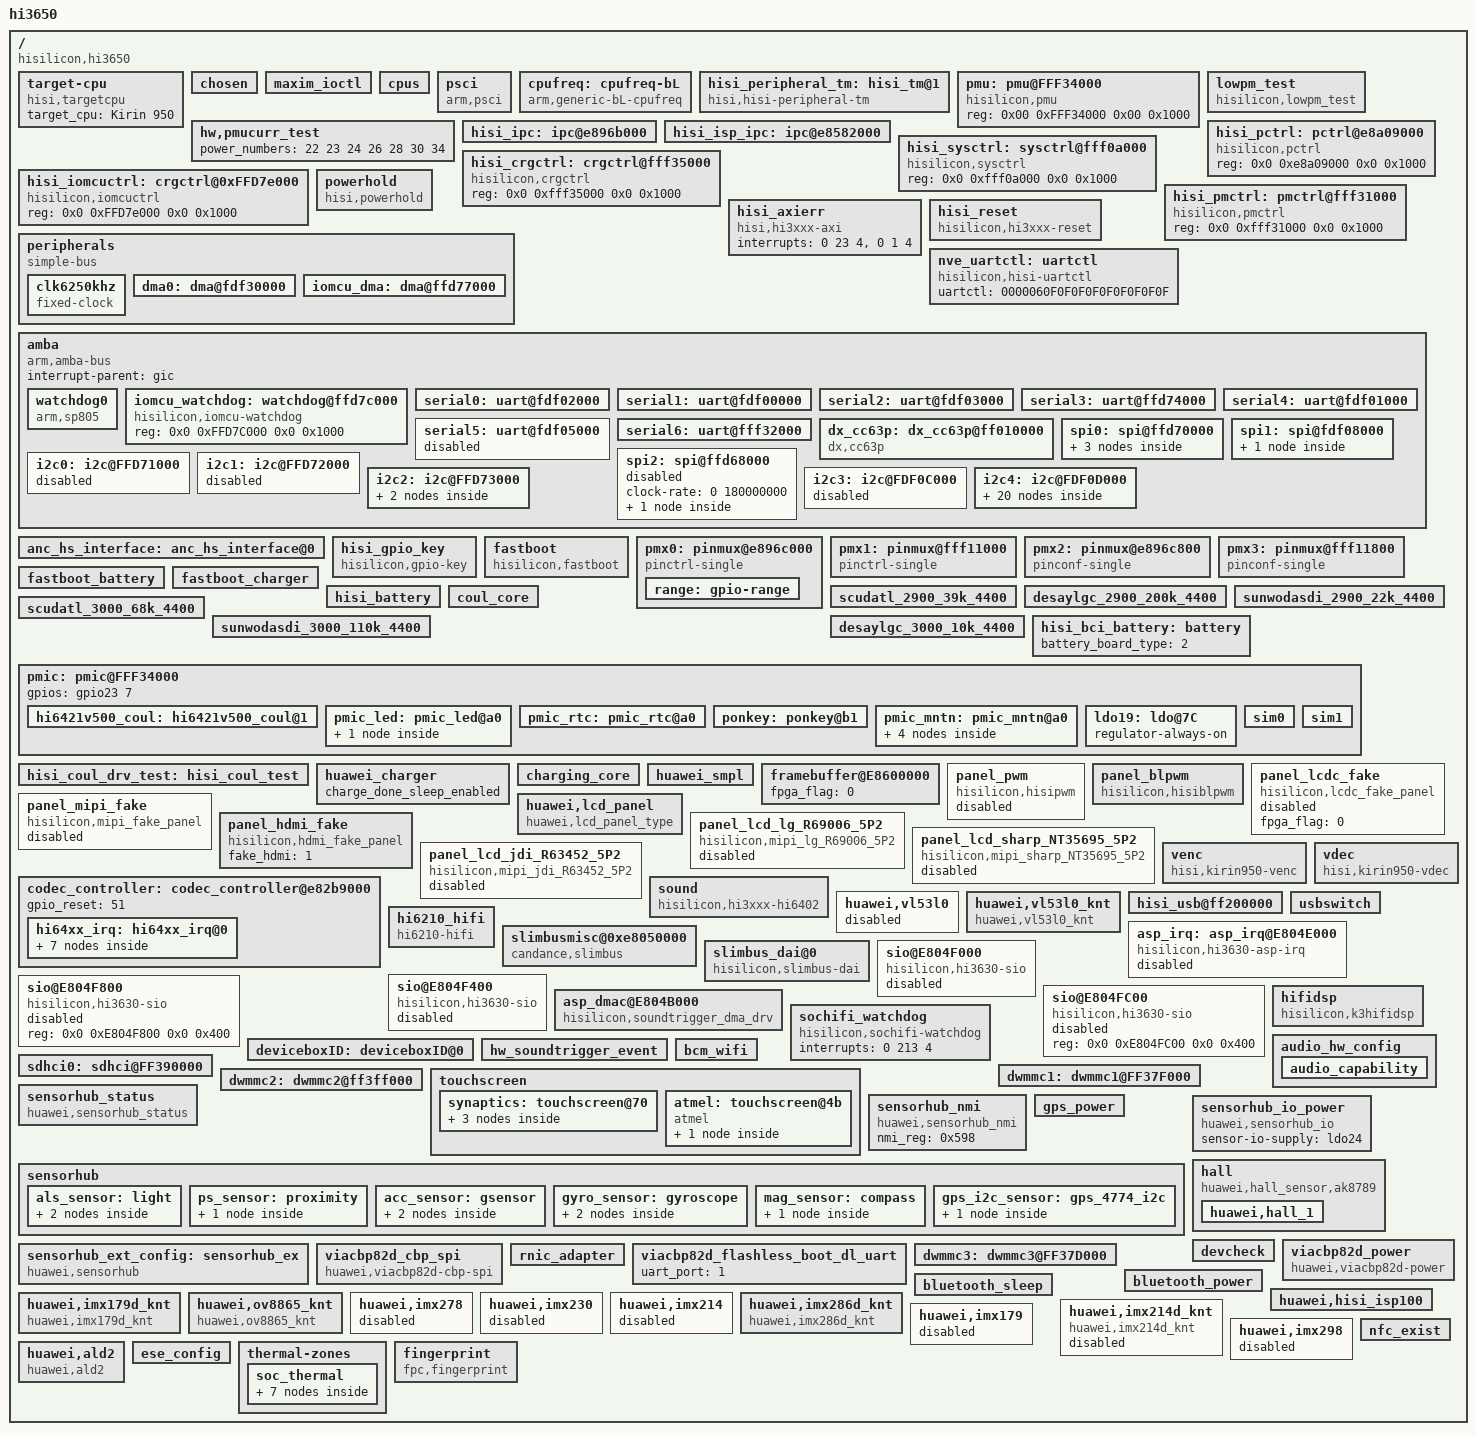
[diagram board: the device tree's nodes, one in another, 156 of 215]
/**
 * Copyright (C) 2014 Hisilicon Ltd.
 *
 *  This program is free software; you can redistribute it and/or modify
 *  it under the terms of the GNU General Public License version 2 as
 *  publishhed by the Free Software Foundation.
 */

/include/ "hisi_3650_cci.dtsi"
/include/ "hisi_3650_gic.dtsi"
/include/ "hisi_3650_timer.dtsi"
/include/ "FRD_TUCL_V0_pin.dtsi"
/include/ "FRD_TUCL_V0_modem_pin.dtsi"
/include/ "hisi_3650.dtsi"
/include/ "hisi_3650_ddrflux.dtsi"
/include/ "huawei_usbswitch.dtsi"
/include/ "hisi_64xx_codec.dtsi"
/include/ "hisi_soundtrigger_event.dtsi"
/include/ "FRD_TUCL_V0_hi6402_pin.dtsi"
/include/ "huawei_audio.dtsi"
/include/ "modem/hisi_modem_balong.dtsi"
/include/ "hisi_6421v500_pmic.dtsi"
/include/ "hisi_freq_autodown.dtsi"
/include/ "hisi_6421v500_pmic_mntn.dtsi"
/include/ "hisi_bci_battery.dtsi"
/include/ "scudatl_2900_39k_4400.dtsi"
/include/ "desaylgc_2900_200k_4400.dtsi"
/include/ "sunwodasdi_2900_22k_4400.dtsi"
/include/ "scudsony_2900_470k_4400.dtsi"
/include/ "scudatl_3000_68k_4400.dtsi"
/include/ "sunwodasdi_3000_110k_4400.dtsi"
/include/ "hisi_battery.dtsi"
/include/ "huawei_charger.dtsi"
/include/ "hisi_coul.dtsi"
/include/ "hisi_6421v500_pmic_led.dtsi"
/include/ "hisi_rtc.dtsi"
/include/ "hisi_3650_vibrator.dtsi"
/include/ "huawei_devdetect.dtsi"
/include/ "hisi_3650_cpu.dtsi"
/include/ "hisi_3650_thermal.dtsi"
/include/ "huawei_connectivity.dtsi"
/include/ "hisi_connectivity.dtsi"
/include/ "huawei_wifi.dtsi"
/include/ "huawei_smartpa.dtsi"
/include/ "huawei_bluetooth.dtsi"
/include/ "huawei_gps.dtsi"
/include/ "hisi_3650_ivp.dtsi"
/include/ "huawei_ext_modem.dtsi"
/include/ "fastboot_battery.dtsi"
/include/ "fastboot_charger.dtsi"
/include/ "hisi_sim_hotplug.dtsi"
/include/ "huawei_smpl.dtsi"
/include/ "huawei_bastet.dtsi"
/include/ "huawei_anc_hs.dtsi"
/include/ "huawei_typec.dtsi"
/include/ "huawei_pmucurr_test.dtsi"
/ {
	#address-cells = <2>;
	#size-cells = <2>;
	model = "hi3650";
	compatible = "hisilicon,hi3650";
	interrupt-parent = <&gic>;
	hisi,boardid = <3 9 0 0>;
	hisi,boardname = "FRD_TUCL_V0";
	hisi,modem_id = <0x3C610000>;
	hisi,platform_num = <4>;
	hisi,provider0 = "HUAWEI_K3";
	hisi,sub_platform_info0 = "Kirin950";
	hisi,provider1 = "BALONG";
	hisi,sub_platform_info1 = "Kirin950";
	hisi,provider2 = "BALONG";
	hisi,sub_platform_info2 = "Kirin950";
	hisi,provider3 = "VIA";
	hisi,sub_platform_info3 = "cpb82d";
	hisi,config_profile = "normal";
	hisi,product_name = "FRD-AL10";
	hisi,userdata_fs_type = "f2fs";

	target-cpu {
		compatible = "hisi,targetcpu";
		target_cpu = "Kirin 950";
	};

	chosen{};

	maxim_ioctl {
		status = "ok";
	};

	cpus {
		status = "ok";
	};

	psci {
		compatible = "arm,psci";
		method = "smc";
		cpu_suspend = <0xc4000001>;
		cpu_off = <0x84000002>;
		cpu_on = <0xc4000003>;
		system_off = <0x84000008>;
		system_reset = <0x84000009>;
	};

	/* cpufreq  device */
	cpufreq: cpufreq-bL {
		compatible = "arm,generic-bL-cpufreq";
		status = "ok";
	};

	hisi_peripheral_tm: hisi_tm@1 {
		compatible = "hisi,hisi-peripheral-tm";
		hisi,peripheral_sensors = <8>;

		hisi,detect_system_h_tm_chanel = <12>;
		hisi,detect_system_h_tm_ntc = "austin_hkadc_soc_temp_table";
		hisi,detect_system_h_tm_state = "enable";
		//austion combine the system_h NTC and charger_ic NTC to one

		hisi,detect_flash_led_tm_chanel = <13>;
		hisi,detect_flash_led_tm_ntc = "austin_hkadc_soc_temp_table";
		hisi,detect_flash_led_tm_state = "enable";

		hisi,detect_charger_tm_chanel = <12>;
		hisi,detect_charger_tm_ntc = "austin_hkadc_soc_temp_table";
		hisi,detect_charger_tm_state = "enable";
		//austion combine the system_h NTC and charger_ic NTC to one

		hisi,detect_pa_0_tm_chanel = <11>;
		hisi,detect_pa_0_tm_ntc = "austin_hkadc_pa_temp_table";
 		hisi,detect_pa_0_tm_state = "enable";

		hisi,detect_pa_1_tm_chanel = <13>;
		hisi,detect_pa_1_tm_ntc = "austin_hkadc_pa_temp_table";
		hisi,detect_pa_1_tm_state = "disable";

		hisi,detect_dcxo0_tm_chanel = <3>;
		hisi,detect_dcxo0_tm_ntc = "austin_hkadc_adc_temp_table";
		hisi,detect_dcxo0_tm_state = "enable";

		hisi,detect_shell_tm_chanel = <7>;
		hisi,detect_shell_tm_ntc = "austin_hkadc_soc_temp_table";
		hisi,detect_shell_tm_state = "enable";

		hisi,detect_Battery_tm_chanel = <10>;
		hisi,detect_Battery_tm_ntc = "austin_hkadc_adc_temp_table";
		hisi,detect_Battery_tm_state = "disable";
	};

	pmu: pmu@FFF34000 {
		compatible = "hisilicon,pmu";
		reg = <0x00 0xFFF34000 0x00 0x1000>;
		status = "ok";
	};

	hw,pmucurr_test{
		power_numbers = <22 23 24 26 28 30 34>;
		status = "ok";
	};

	lowpm_test {
		compatible = "hisilicon,lowpm_test";
		sr_plat_flag = <1>;
		reg = <0x0 0xfff32000 0x0 0x1000>;
		status = "ok";
	};

	hisi_ipc: ipc@e896b000 {
		status = "ok";
	};

	hisi_isp_ipc: ipc@e8582000 {
		status = "ok";
	};

	hisi_sysctrl: sysctrl@fff0a000 {
		compatible = "hisilicon,sysctrl";
		reg = <0x0 0xfff0a000 0x0 0x1000>;
		status = "ok";
	};

	hisi_pctrl: pctrl@e8a09000 {
		compatible = "hisilicon,pctrl";
		reg = <0x0 0xe8a09000 0x0 0x1000>;
		status = "ok";
	};

	hisi_crgctrl: crgctrl@fff35000 {
		compatible = "hisilicon,crgctrl";
		reg = <0x0 0xfff35000 0x0 0x1000>;
		status = "ok";
	};

	hisi_iomcuctrl: crgctrl@0xFFD7e000 {
		compatible = "hisilicon,iomcuctrl";
		reg = <0x0 0xFFD7e000 0x0 0x1000>;
		status = "ok";
	};

	hisi_pmctrl: pmctrl@fff31000 {
		compatible = "hisilicon,pmctrl";
		reg = <0x0 0xfff31000 0x0 0x1000>;
		status = "ok";
	};

	hisi_axierr {
		compatible = "hisi,hi3xxx-axi";
		interrupts = <0 23 4>, <0 1 4>;
		status = "ok";
	};

	powerhold:powerhold {
		compatible = "hisi,powerhold";
		/*gpio204  base address*/
		reg = <0x0 0xFFF0E000 0x0 0x1000>;
		/*gpio204  offset address*/
		offset = <0x4>;
		status = "ok";
	};

	hisi_reset {
		compatible = "hisilicon,hi3xxx-reset";
		status = "ok";
	};

	peripherals {
		compatible = "simple-bus";
		#address-cells = <1>;
		#size-cells = <1>;
		ranges = <0x0 0x00000000 0x0 0xffffffff>;

		clk6250khz: clk6250khz {
			compatible = "fixed-clock";
			#clock-cells = <0>;
			clock-frequency = <6297600>;
			clock-output-names = "clk6250khz";
		};

		dma0: dma@fdf30000 {
			status = "ok";
		};

		iomcu_dma: dma@ffd77000 {
			status = "ok";
		};

	};

	nve_uartctl:uartctl {
		compatible = "hisilicon,hisi-uartctl";
		uartctl = "0000060F0F0F0F0F0F0F0F0F";
	};

	amba {
		#address-cells = <2>;
		#size-cells = <2>;
		compatible = "arm,amba-bus";
		interrupt-parent = <&gic>;
		ranges;

		watchdog0 {
			compatible = "arm,sp805", "arm,primecell";
			reg = <0x0 0xe8a06000 0x0 0x1000>;
			default-timeout = <60>;
			interrupts = <0 44 4>;
			clocks = <&pclk_gate_wd0 &pclk>;
			clock-names = "pclk_wd0", "apb_pclk";
			status = "ok";
		};
		
		iomcu_watchdog: watchdog@ffd7c000 {
			compatible = "hisilicon,iomcu-watchdog";
			reg = <0x0 0xFFD7C000 0x0 0x1000>;
			status = "ok";
		};

		serial0: uart@fdf02000 {
			pinctrl-0 = <>;
			pinctrl-1 = <>;
			clock-rate = <0 19200000>;
			status = "ok";
		};

		serial1: uart@fdf00000 {
			pinctrl-0 = <>;
			pinctrl-1 = <>;
			clock-rate = <0 160000000>;
			status = "ok";
			reset-enable-flag = <1>;
		};

		serial2: uart@fdf03000 {
			clock-rate = <0 19200000>;
			status = "ok";
			reset-enable-flag = <1>;
		};

		serial3: uart@ffd74000 {
			clock-rate = <0 180000000>;
			status = "ok";
			reset-enable-flag = <0>;
		};

		serial4: uart@fdf01000 {
			clock-rate = <0 160000000>;
			status = "ok";
			reset-enable-flag = <1>;
		};

		serial5: uart@fdf05000 {
			clock-rate = <0 19200000>;
			status = "disabled";
			reset-enable-flag = <1>;
		};

		serial6: uart@fff32000 {
			clock-rate = <0 19200000>;
			console-fifo-enable = <1>;
			/* 256k */
			console-fifo-size = <262144>;
			console-fifo-cpuon = <3>;
			status = "ok";
			reset-enable-flag = <0>;
		};


		dx_cc63p: dx_cc63p@ff010000 {
			compatible = "dx,cc63p";
			reg = <0x0 0xff010000 0x0 0x1000>;
			sec-p-buring-supply = <&sec_p>;
			interrupt-parent = <&gic>;
			interrupts = <0 135 4>;
			status = "ok";
		};

		spi0: spi@ffd70000 {
			status = "ok";
			clock-rate = <0 180000000>;
			smc-flag = <1>;
			hardware-mutex = <0x01>;
			pinctrl-names = "default", "idle";
			pinctrl-0 = <&gpio047_pmx_func &gpio048_pmx_func &gpio049_pmx_func &gpio047_cfg_func &gpio048_cfg_func
					&gpio049_cfg_func>;
			pinctrl-1 = <&gpio047_pmx_idle &gpio048_pmx_idle &gpio049_pmx_idle &gpio047_cfg_idle &gpio048_cfg_idle
					&gpio049_cfg_idle>;

			depth_isp: depth_isp@0 {
				compatible = "depth_isp";
				spi-max-frequency = <26000000>;
				reg = <0>;
				pl022,com-mode = <2>;
				pl022,interface = <0>;
				pl022,rx-level-trig = <3>;
				pl022,tx-level-trig = <3>;
				pl022,ctrl-len = <7>;
				pl022,wait-state = <0>;
				pl022,duplex = <0>;
				pl022,slave-tx-disable = <0>;
				
				/*chip-type 1:dummy  2:Al6045  4:Al6010*/
				depth_isp,chip_type = <1>;
				depth_isp,reset_gpio = <7>;
				depth_isp,cs_gpio = <52>;
				depth_isp,irq_gpio = <56>;
				pinctrl-names = "default", "idle";
				pinctrl-0 = <&gpio007_pmx_func
					 &gpio052_pmx_func
					 &gpio056_pmx_func
					 &gpio007_cfg_func
					 &gpio052_cfg_func
					 &gpio056_cfg_func>;

				pinctrl-1 = <&gpio007_pmx_idle
					 &gpio052_pmx_idle
					 &gpio056_pmx_idle
					 &gpio007_cfg_idle
					 &gpio052_cfg_idle
					 &gpio056_cfg_idle>;

			};

			spi_dev1: spi_dev1@1 {
				compatible = "spi_dev1";
				spi-max-frequency = <13000000>;
				reg = <1>;
				pl022,com-mode = <0>;
				pl022,interface = <0>;
				pl022,rx-level-trig = <3>;
				pl022,tx-level-trig = <3>;
				pl022,ctrl-len = <7>;
				pl022,wait-state = <0>;
				pl022,duplex = <0>;
				pl022,slave-tx-disable = <0>;
			};

			spi_dev3: spi_dev3@3 {
				compatible = "spi_dev3";
				spi-max-frequency = <13000000>;
				reg = <3>;
				pl022,com-mode = <0>;
				pl022,interface = <0>;
				pl022,rx-level-trig = <3>;
				pl022,tx-level-trig = <3>;
				pl022,ctrl-len = <7>;
				pl022,wait-state = <0>;
				pl022,duplex = <0>;
				pl022,slave-tx-disable = <0>;
			};
		};

		spi1: spi@fdf08000 {
			status = "ok";
			smc-flag = <1>;
			clock-rate = <0 48000000>;
			pinctrl-names = "default", "idle";
			pinctrl-0 = <&gpio011_pmx_func &gpio012_pmx_func &gpio013_pmx_func
					&gpio011_cfg_func &gpio012_cfg_func &gpio013_cfg_func>;
			pinctrl-1 = <&gpio011_pmx_idle &gpio012_pmx_idle &gpio013_pmx_idle
					&gpio011_cfg_idle &gpio012_cfg_idle &gpio013_cfg_idle>;
			spi_dev10: spi_dev10@10 {
					compatible = "spi_dev10";
					fpga_flag = <1>;
					spi-max-frequency = <100000>;
					reg = <0>;
					pl022,com-mode = <0>;
					pl022,interface = <0>;
					pl022,rx-level-trig = <3>;
					pl022,tx-level-trig = <3>;
					pl022,ctrl-len = <7>;
					pl022,wait-state = <0>;
					pl022,duplex = <0>;
					pl022,slave-tx-disable = <0>;
			};
		};

		spi2: spi@ffd68000 {
			status = "disabled";
			clock-rate = <0 180000000>;
			spi_dev20: spi_dev20@20 {
				compatible = "spi_dev20";
				fpga_flag = <1>;
				spi-max-frequency = <100000>;
				reg = <0>;
				pl022,com-mode = <0>;
				pl022,interface = <0>;
				pl022,rx-level-trig = <3>;
				pl022,tx-level-trig = <3>;
				pl022,ctrl-len = <7>;
				pl022,wait-state = <0>;
				pl022,duplex = <0>;
				pl022,slave-tx-disable = <0>;
			};
		};

		/* I2C0 ~ I2C4 */
		i2c0: i2c@FFD71000 {
			status = "disabled";
			clock-rate = <0 19200000>;
			pinctrl-names = "default", "idle";
			pinctrl-0 = <&gpio183_pmx_func &gpio184_pmx_func &gpio183_cfg_func &gpio184_cfg_func>;
			pinctrl-1 = <&gpio183_pmx_idle &gpio184_pmx_idle &gpio183_cfg_idle &gpio184_cfg_idle>;
			cs-gpios = <&gpio22 7 0>, <&gpio23 0 0>;
		};

		i2c1: i2c@FFD72000 {
			status = "disabled";
			clock-rate = <0 19200000>;
			pinctrl-names = "default", "idle";
			pinctrl-0 = <&gpio185_pmx_func &gpio186_pmx_func &gpio185_cfg_func &gpio186_cfg_func>;
			pinctrl-1 = <&gpio185_pmx_idle &gpio186_pmx_idle &gpio185_cfg_idle &gpio186_cfg_idle>;
			cs-gpios = <&gpio23 1 0>, <&gpio23 2 0>;
		};

		i2c2: i2c@FFD73000 {
			status = "ok";
			clock-rate = <0 19200000>;
			pinctrl-names = "default", "idle";
			pinctrl-0 = <&gpio187_pmx_func &gpio188_pmx_func &gpio187_cfg_func &gpio188_cfg_func>;
			pinctrl-1 = <&gpio187_pmx_idle &gpio188_pmx_idle &gpio187_cfg_idle &gpio188_cfg_idle>;
			cs-gpios = <&gpio23 3 0>, <&gpio23 4 0>;

			shtsc@18 {
				status = "disabled";
			};

			synaptics_dsx@20 {
				status = "disabled";
			};
		};

		i2c3: i2c@FDF0C000 {
			status = "disabled";
			clock-rate = <0 120000000>;
			pinctrl-names = "default", "idle";
			pinctrl-0 = <&gpio009_pmx_func &gpio010_pmx_func &gpio009_cfg_func &gpio010_cfg_func>;
			pinctrl-1 = <&gpio009_pmx_idle &gpio010_pmx_idle &gpio009_cfg_idle &gpio010_cfg_idle>;
			cs-gpios = <&gpio1 1 0>, <&gpio1 2 0>;
		};

		i2c4: i2c@FDF0D000 {
			status = "ok";
			clock-rate = <0 120000000>;
			pinctrl-names = "default", "idle";
			pinctrl-0 = <&gpio037_pmx_func &gpio038_pmx_func &gpio037_cfg_func &gpio038_cfg_func>;
			pinctrl-1 = <&gpio037_pmx_idle &gpio038_pmx_idle &gpio037_cfg_idle &gpio038_cfg_idle>;
			cs-gpios = <&gpio4 5 0>, <&gpio4 6 0>;

			max98925_smartpa_l:smartpa@31 {
				gain = <0x14>;
				gain_incall = <0x14>;
				status = "ok";
			};

			anc_max14744: anc_max14744@15{
				gpio_int = <&gpio26 6 0>;
				pinctrl-0 = <&gpio214_pmx_func &gpio214_cfg_func>;
				pinctrl-1 = <&gpio214_pmx_idle &gpio214_cfg_idle>;
				anc_hs_btn_hook_min_voltage = <155>;
				anc_hs_btn_hook_max_voltage = <190>;
				anc_hs_btn_volume_up_min_voltage = <195>;
				anc_hs_btn_volume_up_max_voltage = <245>;
				anc_hs_btn_volume_down_min_voltage = <250>;
				anc_hs_btn_volume_down_max_voltage = <308>;
				status = "ok";
			};

			bq25892_charger: bq25892_charger@6B {
				bat_comp = <60>;
				vclamp = <192>;
				rilim = <150>;
				adc_channel_iin = <5>;
				fcp_support = <1>;
				status = "ok";
			};

			big-core-mon@40 {
				compatible = "hisilicon,big-core-mon";
				reg = <0x40>;
				status = "disabled";
			};

			little-core-mon@41 {
				compatible = "hisilicon,little-core-mon";
				reg = <0x41>;
				status = "ok";
			};

			fairchild_fsa9685: fsa9685@25 {
				usbid-enable = <0>;
				status = "ok";
			};

			gpu-mon@42 {
				compatible = "hisilicon,gpu-mon";
				reg = <0x42>;
				status = "ok";
			};

			ddr-mon@44 {
				compatible = "hisilicon,ddr-mon";
				reg = <0x44>;
				status = "ok";
			};

			peri-mon@45 {
				compatible = "hisilicon,peri-mon";
				reg = <0x45>;
				status = "ok";
			};

			battery-mon@46 {
				compatible = "hisilicon,battery-mon";
				reg = <0x46>;
				status = "ok";
			};

			vsys-mon@47 {
				compatible = "hisilicon,vsys-mon";
				reg = <0x47>;
				status = "disabled";
			};

			ti-drv2605@5a {
				compatible = "ti,drv2605";
				reg = <0x5a>;
				ti,label = "vibrator";
				gpio-enable = <&gpio15 5 0>;
				ti,max-timeout-ms = <10000>;
				ti,reduce-timeout-ms = <12>;
				lra_rated_voltage = <0x34>;
				lra_rtp_strength = <0x7F>;
				status = "ok";
			};

			pn547_nfc:nfc@28 {
				compatible = "hisilicon,pn547_nfc";
				reg = <0x28>;
				clocks = <&clk_gate_out0>;
				clock-names = "clk_out0";
				pinctrl-names = "default","idle";
				pinctrl-0 = <&gpio014_pmx_func &gpio014_cfg_func>;
				pinctrl-1 = <&gpio014_pmx_idle &gpio014_cfg_idle>;
				pn547,ven = <&gpio16 4 0>;
				pn547,irq = <&gpio26 0 0>;
				pn547,dload = <&gpio12 3 0>;
				clk_status="pmu";
				nfc_card_num = <0x2>;
				nfc_nxp_name = "libnfc_nxp_frd.conf";
				nfc_brcm_conf_name = "libnfc_brcm_frd.conf";
				nfc_chip_type = "pn66t";
				nfc_ese_type = "p61";
				/* nfc svdd switch:pull up for eSE, pull down for sim1 */
				nfc_svdd_sw = "true";
				/* nfc power on type:gpio,hisi_pmic,regulator_bulk */
				nfc_on_type = "gpio";
				status = "ok";
			};

			huawei,ina231A{
				compatible = "huawei,ina231_0";
				reg = <0x40>;
				gpios = <&gpio28 2 0 >;
				status = "ok";
			};

			tps65132_phy: tps65132@3e {
				compatible = "hisilicon,tps65132_phy";
				reg = <0x3e>;
				gpios = <&gpio6 5 0>, <&gpio15 0 0>;
				status = "ok";
			};

			huawei,lm3646@67{
				pinctrl-names = "default", "idle";
				pinctrl-0 = <&gpio024_hi6402_pinctrl_func>;
				pinctrl-1 = <&gpio024_hi6402_pinctrl_idle>;
				huawei,flash-pin = <248 999 999>;
				huawei,need-wakelock = <1>;
				status = "ok";
			};

			hisi,ncp6925@50{
				compatible = "hisi,ncp6925";
				reg = <0x52>;
				hisi,pmic_name = "ncp6925";
				hisi,pmic_index = <0>;
				hisi,slave_address = <0x52>;
				pinctrl-names = "default", "idle";
				pinctrl-0 = <&gpio133_pmx_func &gpio133_cfg_func>;
				pinctrl-1 = <&gpio133_pmx_idle &gpio133_cfg_idle>;
				hisi,pmic-pin = <133 999 999>;
				hisi,pmic-voltage = <0x0 0x1 0x2 0x3 0x4 0x5 0x6>;
				status = "ok";
			};

			tusb320_typec:typec@47{
				reg = <0x47>;
				tusb320_typec,gpio_enb = <&gpio30 7 0>;
				tusb320_typec,gpio_intb = <&gpio27 5 0>;
				tusb320_gpio_enb = <1>;
				typec_trigger_otg = <1>;
				tusb320_mdelay = <100>;
				status = "ok";
			};

			fusb301_typec: typec@21 {
				reg = <0x21>;
				fusb301_typec,gpio_enb = <&gpio30 7 0>;
				fusb301_typec,gpio_intb = <&gpio27 5 0>;
				fusb301_gpio_enb = <1>;
				typec_trigger_otg = <1>;
				status = "ok";
			};

			pericom30216_typec: typec@1d {
				reg = <0x1d>;
				pericom30216_typec,gpio_enb = <&gpio30 7 0>;
				pericom30216_typec,gpio_intb = <&gpio27 5 0>;
				pericom30216_gpio_enb = <1>;
				typec_trigger_otg = <1>;
				pericom30216_mdelay = <50>;
				status = "ok";
			};
		};
	};
	/* end amba */

	anc_hs_interface: anc_hs_interface@0{
		status = "ok";
	};

	hisi_gpio_key {
		compatible = "hisilicon,gpio-key";
		pinctrl-names = "default", "idle";
		pinctrl-0 = <&gpio201_cfg_func &gpio202_cfg_func &gpio220_cfg_func>;
		pinctrl-1 = <&gpio201_cfg_idle &gpio202_cfg_idle &gpio220_cfg_idle>;
		gpio-keyup,gpio-irq = <&gpio25 1 0>;
		gpio-keydown,gpio-irq = <&gpio25 2 0>;
		gpio-keysmart,gpio-irq = <&gpio27 4 0>;
		support_smart_key = <1>;
		status = "ok";
	};

	fastboot {
		compatible = "hisilicon,fastboot";
		i2c3-pin = <0>;
		gpio-keyup = <201>;
		gpio-keydown = <202>;
		uart-board-type = <3>;
		/*UDP_TYPE 0,PRODUCT 1,FPGA 2,EMU 3*/
		lpm3-board-type = <1>;
		jtagtosd-board-type = <1>;

		/*motor*/
		motor-vib_type = <1>;
		motor-gpio_en = <125>;
	};

	pmx0: pinmux@e896c000 {
		compatible = "pinctrl-single", "pinctrl-single0";
		reg = <0x0 0xe896c000 0x0 0x228>;
		#gpio-range-cells = <3>;
		//ranges;
		pinctrl-single,register-width = <32>;
		pinctrl-single,function-mask = <7>;
		/* pin base, nr pins & gpio function */
		pinctrl-single,gpio-range = <&range 0 138 0>;
		range: gpio-range {
			#pinctrl-single,gpio-range-cells = <3>;
		};
	};

	pmx1: pinmux@fff11000 {
		compatible = "pinctrl-single", "pinctrl-single1";
		reg = <0x0 0xfff11000 0x0 0xac>;
		#gpio-range-cells = <3>;
		//ranges;
		pinctrl-single,register-width = <32>;
		pinctrl-single,function-mask = <7>;
		/* pin base, nr pins & gpio function */
		pinctrl-single,gpio-range = <&range 0 43 0>;
	};

	pmx2: pinmux@e896c800 {
		compatible = "pinconf-single", "pinctrl-single2";
		reg = <0x0 0xe896c800 0x0 0x234>;
		//ranges;
		pinctrl-single,register-width = <32>;
	};

	pmx3: pinmux@fff11800 {
		compatible = "pinconf-single", "pinctrl-single3";
		reg = <0x0 0xfff11800 0x0 0xbc>;
		//ranges;
		pinctrl-single,register-width = <32>;
	};
	
	/*power start*/
	fastboot_battery:fastboot_battery {
		status = "ok";
	};

	fastboot_charger:fastboot_charger {
		charger_cd = <177>;
		chip_i2c_num = <4>;
		ichrg_pre_limit = <256>;
		hw_charger_type = <3>;
		status = "ok";
	};

	hisi_battery:hisi_battery {
		batt_name = <&scudatl_2900_39k_4400 &desaylgc_2900_200k_4400 &sunwodasdi_2900_22k_4400 &scudatl_3000_68k_4400 &sunwodasdi_3000_110k_4400 &desaylgc_3000_10k_4400 &scudsony_2900_470k_4400>;
		status = "ok";
	};
	scudatl_2900_39k_4400:scudatl_2900_39k_4400 {
		segment_para =
				"-32767","4150","2900","4208","50",
				"4150","4450","2030","4400","0";
	};
	desaylgc_2900_200k_4400:desaylgc_2900_200k_4400 {
		segment_para =
				"-32767","4150","2900","4208","50",
				"4150","4450","2030","4400","0";
	};
	sunwodasdi_2900_22k_4400:sunwodasdi_2900_22k_4400 {
		segment_para =
				"-32767","4150","2900","4208","50",
				"4150","4450","2030","4400","0";
	};
	scudatl_3000_68k_4400:scudatl_3000_68k_4400 {
		fcc_temp = <2979 2977 2979 2995 2980 2964>;
		segment_para =
				"-32767","4150","3000","4208","50",
				"4150","4450","2100","4400","0";
	};
	sunwodasdi_3000_110k_4400:sunwodasdi_3000_110k_4400 {
		fcc_temp = <2954 2949 2944 2980 2967 2939>;
		segment_para =
				"-32767","4150","3000","4208","50",
				"4150","4450","2100","4400","0";
	};
	desaylgc_3000_10k_4400:desaylgc_3000_10k_4400 {
		fcc = <3000>;
		default_rbatt_mohm = <100>;
		id_identify_min = <0>;
		id_identify_max = <751>;
		id_voltage_min = <496>;
		id_voltage_max = <553>;
		vbat_max = <4400>;
		temp_para =
					"-32767","0","-1","0","4100","0",
					"0","10","-1","900","4384","3",
					"10","45","-1","-1","4384","3",
					"45","50","-1","1050","4384","3",
					"50","32767","-1","0","4384","0";
		vbat_para =
					"-32767","3400","-1","820","0",
					"3400","32767","-1","-1","0";
		segment_para =
					"-32767","4150","3000","4208","50",
					"4150","4450","2100","4384","0";
		batt_brand = "desaylgc";
		fcc_temp = <2929 2927 2929 2945 2930 2914>;
		fcc_sf_x = <0 100 200 300 400 500>;
		fcc_sf_y = <100 96 94 92 90 88>;
		fcc_sf_cols = <6>;
		pc_sf_rows = <1>;
		pc_sf_cols = <1>;
		pc_sf_row_entries = <0>;
		pc_sf_percent = <100>;
		pc_sf_sf = <100>;
		rbatt_sf_rows = <28>;
		rbatt_sf_cols = <6>;
		rbatt_sf_percent = <100 95 90 85 80 75 70 65 60 55 50 45 40 35 30 25 20 15 10 9 8 7 6 5 4 3 2 1>;
		rbatt_sf_sf = <
		               2043 944 393 133 107 97
		               2042 944 393 133 107 97
		               1895 952 398 134 109 98
		               1757 947 400 138 112 99
		               1661 945 416 144 115 102
		               1617 930 430 151 119 104
		               1430 872 455 163 125 108
		               1412 815 402 180 135 112
		               1416 822 374 183 147 121
		               1405 812 361 137 117 103
		               1423 817 360 131 108 99
		               1472 856 365 133 110 99
		               1529 921 370 137 112 102
		               1606 996 386 143 117 107
		               1700 1091 419 142 119 108
		               1818 1210 463 138 108 100
		               1965 1370 515 134 106 98
		               2163 1593 595 137 107 98
		               2437 1409 560 138 110 101
		               2696 1336 515 140 110 103
		               3044 1494 538 140 111 103
		               3435 1687 573 140 112 104
		               3896 1902 643 142 113 103
		               4392 2178 722 141 110 101
		               5108 2531 779 144 110 100
		               6069 3034 905 149 112 103
		               7448 3877 1151 165 117 104
		               10032 5481 1732 399 146 113
		              >;
		pc_temp_ocv_rows = <29>;
		pc_temp_ocv_cols = <6>;
		pc_temp_ocv_percent = <100 95 90 85 80 75 70 65 60 55 50 45 40 35 30 25 20 15 10 9 8 7 6 5 4 3 2 1>;
		pc_temp_ocv_ocv = <
		                   4386 4383 4382 4374 4367 4361
		                   4289 4302 4309 4312 4306 4301
		                   4221 4240 4250 4253 4248 4243
		                   4159 4183 4192 4195 4190 4185
		                   4103 4129 4137 4139 4134 4129
		                   4056 4072 4087 4085 4080 4077
		                   3967 3998 4030 4036 4032 4028
		                   3926 3938 3962 3986 3984 3983
		                   3892 3902 3918 3941 3942 3941
		                   3855 3864 3879 3887 3888 3887
		                   3828 3831 3846 3853 3853 3853
		                   3809 3809 3821 3828 3828 3827
		                   3793 3796 3799 3807 3808 3806
		                   3779 3786 3785 3791 3791 3789
		                   3766 3776 3776 3776 3775 3772
		                   3752 3763 3767 3760 3754 3742
		                   3738 3743 3749 3740 3733 3720
		                   3724 3717 3724 3714 3708 3695
		                   3704 3700 3696 3691 3684 3672
		                   3697 3695 3694 3690 3683 3671
		                   3689 3690 3691 3688 3681 3670
		                   3679 3686 3687 3685 3679 3668
		                   3667 3678 3682 3679 3674 3662
		                   3646 3663 3669 3658 3659 3643
		                   3617 3633 3638 3616 3623 3604
		                   3573 3585 3588 3559 3571 3553
		                   3509 3516 3517 3482 3503 3484
		                   3406 3410 3411 3374 3403 3384
		                   3200 3200 3200 3200 3200 3200
		                  >;
	};

	hisi_bci_battery:battery {
		battery_board_type = <2>; /*0:sft 1:udp 2:asic*/
		status = "ok";
	}; 

	coul_core:coul_core {
		status = "ok";
		r_pcb = <0>;
		last_soc_enable = <1>;
		startup_delta_soc = <10>;
		soc_at_term = <98>;
		ntc_compensation_is = <1>;
		ntc_temp_compensation_para =
			"2500", "50",
			"2000", "20";
	};

	pmic: pmic@FFF34000 {
		gpios = <&gpio23 7 0>;
		hi6421v500_coul: hi6421v500_coul@1 {
			status = "ok";
		};

		pmic_led: pmic_led@a0 {
			status = "ok";
			/* Reduced the green led current, 0x0 means 1.0mA */
			led@a1 {
				hisilicon,each_max_iset = <0x0>;
			};
		};

		pmic_rtc: pmic_rtc@a0 {
			status = "ok";
		};

		ponkey:ponkey@b1{
			status = "ok";
		};

		pmic_mntn: pmic_mntn@a0 {
			status = "ok";
			/*ldo2,1,0, buck4-0; ldo11-7,5-3;   ldo20,19,17-12;  ldo28-21;     classd,x,x,x,ldo32-29;   buck4-0*/
			hisilicon,reset-when-ocp = <1 0 1 1 1 1 1 1   0 1 0 1 1 1 1 0   1 1 1 0 1 0 1 0  0 1 1 1 1 1 0 1   1 0 0 0 1 1 1 1    1 1 1 1 1 0 0 0 >;
			hisilicon,dsm-ocp-reset-mask = <0xFD 0x3A 0x10 0xA6 0x41 0x1F 0xFF 0xFF 0x00>;
			OCP@a2 {
				hisilicon,inacceptable-event = <0xBA>;
			};

			OCP@a3 {
				hisilicon,inacceptable-event = <0x30>;
			};

			OCP@a4 {
				hisilicon,inacceptable-event = <0xE7>;
			};

			OCP@a5 {
				hisilicon,inacceptable-event = <0x41>;
			};
		};
	};

	hisi_coul_drv_test:hisi_coul_test {
		status = "ok";
	};

	huawei_charger: huawei_charger {
		status = "ok";
		charge_done_sleep_enabled;
	};

	charging_core:charging_core {
		iin_ac = <2000>;
		ichg_ac = <2100>;
		iin_fcp = <2000>;
		ichg_fcp = <3000>;
		ichg_usb = <512>;
		iin_typech = <2000>;
		ichg_typech = <2100>;
		typec_support = <1>;
		iterm = <100>;
		vdpm_para =
			"-32767", "80", "4520", "0",
			"80", "90", "4600", "0",
			"90", "32767", "4700", "0";
		status = "ok";

	};

	huawei_smpl: huawei_smpl{
		status = "ok";
	};
	
	/*power end*/

	/* display start */
	framebuffer@E8600000 {
		fpga_flag = <0>;
	};

	panel_pwm {
		#address-cells = <2>;
		#size-cells = <2>;
		compatible = "hisilicon,hisipwm";
		reg = <0 0xE8A04000 0 0x1000>;
		clocks = <&clk_gate_pwm>;
		clock-names = "clk_pwm";
		pinctrl-names = "default","idle";
		pinctrl-0 = <&gpio182_pmx_func &gpio182_cfg_func>;
		pinctrl-1 = <&gpio182_pmx_idle &gpio182_cfg_idle>;
		fpga_flag = <0>;
		status = "disabled";
	};

	panel_blpwm {
		#address-cells = <2>;
		#size-cells = <2>;
		compatible = "hisilicon,hisiblpwm";
		reg = <0 0xFFD75000 0 0x1000>;
		clocks = <&clk_gate_blpwm>;
		clock-names = "clk_blpwm";
		pinctrl-names = "default","idle";
		pinctrl-0 = <&gpio181_pmx_func &gpio182_pmx_func &gpio181_cfg_func &gpio182_cfg_func>;
		pinctrl-1 = <&gpio181_pmx_idle &gpio182_pmx_idle &gpio181_cfg_idle &gpio182_cfg_idle>;
		fpga_flag = <0>;
		status = "ok";
	};

	panel_lcdc_fake {
		#address-cells = <2>;
		#size-cells = <2>;
		compatible = "hisilicon,lcdc_fake_panel";
		fpga_flag = <0>;
		status = "disabled";
	};

	panel_mipi_fake {
		#address-cells = <2>;
		#size-cells = <2>;
		compatible = "hisilicon,mipi_fake_panel";
		//gpio_lcd_n5v5_enable, gpio_lcd_bl_enable, gpio_lcd_p5v5_enable, gpio_lcd_reset, gpio_lcd_id
		gpios = <&gpio15 0 0>, <&gpio15 6 0>,  <&gpio6 5 0>, <&gpio2 4 0>, <&gpio9 7 0>, <&gpio16 3 0>;
		gpio_nums = <120 126 53 20 21 79 131>;
		fpga_flag = <0>;
		status = "disabled";
	};

	huawei,lcd_panel {
		lcd_id_match_tab = <0 1 4>;
		detect_type = <0>;
		compatible = "huawei,lcd_panel_type";
		support_lcd_type = "JDI_R63452_5P2_LCD","SHARP_NT35695_5P2_LCD","LG_R69006_5P2_LCD";
		gpio_cfg_addr = <0xE896C93c 0xE896C978>;
		gpio_id = <79 94>;
	};


	panel_hdmi_fake {
		#address-cells = <2>;
		#size-cells = <2>;
		compatible = "hisilicon,hdmi_fake_panel";
		fake_hdmi = <1>;
		status = "ok";
	};

	panel_lcd_lg_R69006_5P2{
		status = "disabled";
		lcdanalog-vcc-supply = <&ldo17>;
		lcdio-vcc-supply = <&ldo4>;
		compatible = "hisilicon,mipi_lg_R69006_5P2";
		#size-cells = <2>;
		#address-cells = <2>;
		pinctrl-0 = <&gpio002_hi6402_pinctrl_func &gpio021_pmx_func &gpio021_cfg_func &gpio094_cfg_func &gpio079_cfg_func &gpio020_cfg_func &gpio126_cfg_func &gpio120_cfg_func &gpio053_cfg_func>;
		pinctrl-1 = <&gpio002_hi6402_pinctrl_idle &gpio021_pmx_idle &gpio021_cfg_idle &gpio094_cfg_idle &gpio079_cfg_idle &gpio020_cfg_idle &gpio126_cfg_idle &gpio120_cfg_idle &gpio053_cfg_idle>;
		pinctrl-names = "default", "idle";
		gpio_nums = <120 126 53 20 21 79 94>;
		gpios = <&gpio15 0 0>, <&gpio15 6 0>,  <&gpio6 5 0>, <&gpio2 4 0>, <&gpio9 7 0>, <&gpio11 6 0>;
		lcd-bl-type = <4>;
	};

	panel_lcd_sharp_NT35695_5P2{
		status = "disabled";
		lcdanalog-vcc-supply = <&ldo17>;
		lcdio-vcc-supply = <&ldo4>;
		compatible = "hisilicon,mipi_sharp_NT35695_5P2";
		#size-cells = <2>;
		#address-cells = <2>;
		pinctrl-0 = <&gpio002_hi6402_pinctrl_func &gpio021_pmx_func &gpio021_cfg_func &gpio094_cfg_func &gpio079_cfg_func &gpio020_cfg_func &gpio126_cfg_func &gpio120_cfg_func &gpio053_cfg_func>;
		pinctrl-1 = <&gpio002_hi6402_pinctrl_idle &gpio021_pmx_idle &gpio021_cfg_idle &gpio094_cfg_idle &gpio079_cfg_idle &gpio020_cfg_idle &gpio126_cfg_idle &gpio120_cfg_idle &gpio053_cfg_idle>;
		pinctrl-names = "default", "idle";
		gpio_nums = <120 126 53 20 21 79 94>;
		gpios = <&gpio15 0 0>, <&gpio15 6 0>,  <&gpio6 5 0>, <&gpio2 4 0>, <&gpio9 7 0>, <&gpio11 6 0>;
		lcd-bl-type = <4>;
	};

	panel_lcd_jdi_R63452_5P2{
		status = "disabled";
		lcdanalog-vcc-supply = <&ldo17>;
		lcdio-vcc-supply = <&ldo4>;
		compatible = "hisilicon,mipi_jdi_R63452_5P2";
		#size-cells = <2>;
		#address-cells = <2>;
		pinctrl-0 = <&gpio002_hi6402_pinctrl_func &gpio021_pmx_func &gpio021_cfg_func &gpio094_cfg_func &gpio079_cfg_func &gpio020_cfg_func &gpio126_cfg_func &gpio120_cfg_func &gpio053_cfg_func>;
		pinctrl-1 = <&gpio002_hi6402_pinctrl_idle &gpio021_pmx_idle &gpio021_cfg_idle &gpio094_cfg_idle &gpio079_cfg_idle &gpio020_cfg_idle &gpio126_cfg_idle &gpio120_cfg_idle &gpio053_cfg_idle>;
		pinctrl-names = "default", "idle";
		gpio_nums = <120 126 53 20 21 79 94>;
		gpios = <&gpio15 0 0>, <&gpio15 6 0>,  <&gpio6 5 0>, <&gpio2 4 0>, <&gpio9 7 0>, <&gpio11 6 0>;
		lcd-bl-type = <4>;
	};
	/* display end */

    	venc{
		compatible = "hisi,kirin950-venc";
		reg = <0x0 0xe8900000 0x0 0x10000>;
		interrupts = <0 256 4>;
		clocks = <&clk_gate_venc>;
		clock-names = "clk_venc";
		ldo_venc-supply = <&venc>;
		status = "ok";
	};
	vdec{
		compatible = "hisi,kirin950-vdec";
		reg = <0x0 0xe8800000 0x0 0x100000>;
		interrupts = <0 257 4>;
		clocks = <&clk_gate_vdec>;
		clock-names = "clk_vdec";
		dec_outstanding_qos = <0x0>;
		dec_outstanding_bw = <0x0>;
        dec_clk_rate = <400000000>;
		ldo_vdec-supply = <&vdec>;
		status = "ok";
	};

	/* audio device beg */
	codec_controller: codec_controller@e82b9000 {
		gpio_reset = <51>;
		status = "ok";

		hi64xx_irq: hi64xx_irq@0 {
			status = "ok";

			hi6402_codec: hi6402_codec@0{
				hisilicon,mic_num = <2>;
				status = "ok";
			};

			hi6403_codec: hi6403_codec@0{
				hisilicon,mic_num = <2>;
				status = "disabled";
			};

			gpio28: gpio@0{
				status = "ok";
			};
			gpio29: gpio@1{
				status = "ok";
			};
			gpio30: gpio@2{
				status = "ok";
			};
			gpio31: gpio@3{
				status = "ok";
			};
			pmx4: hi6402_pinctrl {
				status = "ok";
			};
		};
	};

	sound {
		compatible = "hisilicon,hi3xxx-hi6402";
		status = "ok";
	};

    /* camera laser */
	huawei,vl53l0 {
		status = "disabled";
	};

	huawei,vl53l0_knt {
		compatible = "huawei,vl53l0_knt";
		product_name = "KNIGHT";
		huawei,laser_name = "VL53L0_ST";
		huawei,i2c_idx = <0>;
		status = "ok";
	};

	hisi_usb@ff200000 {
		usbldo10-supply = <&ldo10>;
	};

	usbswitch: usbswitch {
		status = "ok";
	};

	hi6210_hifi {
		compatible = "hi6210-hifi";
		status = "ok";
	};

	asp_irq: asp_irq@E804E000{
		compatible = "hisilicon,hi3630-asp-irq";
		status = "disabled";
	};

	slimbusmisc@0xe8050000 {
		compatible = "candance,slimbus";
		reg = <0x0 0xe8050000 0x0 0xb00>,
			<0x0 0xe804e000 0x0 0xa000>,
			<0x0 0xfff0a000 0x0 0x1000>;
		interrupts = <0x0 0x96 0x4>;
		interrupt-names = "asp_irq_slimbus";
		slimbus-reg-supply = <&asp>;
		pinctrl-names = "default", "idle";
		pinctrl-0 = <&gpio189_pmx_func
		&gpio190_pmx_func>;
		pinctrl-1 = <&gpio189_pmx_idle
		&gpio190_pmx_idle>;
		slimbus-ssi-sel = "slimbus";
		asp_power_state_offset = <0x0DC>;
		platform-type   = "ASIC";
		status = "ok";
	};

	slimbus_dai@0 {
		compatible = "hisilicon,slimbus-dai";
		status = "ok";
	};

	sio@E804F000 {		
		compatible = "hisilicon,hi3630-sio";
		reg = <0x0 0xE804F000 0x0 0x400>;
		sio-audio-supply = <&asp>;
		/* wbd
		pinctrl-names = "default", "idle";
		pinctrl-0 = <&gpio183_pmx_func
				&gpio184_pmx_func
				&gpio185_pmx_func
				&gpio186_pmx_func
				&gpio183_cfg_func
				&gpio184_cfg_func
				&gpio185_cfg_func
				&gpio186_cfg_func>;
		pinctrl-1 = <&gpio183_pmx_idle
				&gpio184_pmx_idle
				&gpio185_pmx_idle
				&gpio186_pmx_idle
				&gpio183_cfg_idle
				&gpio184_cfg_idle
				&gpio185_cfg_idle
				&gpio186_cfg_idle>;
		*/
		status = "disabled";
	};

	sio@E804F400 {
		compatible = "hisilicon,hi3630-sio";
		status = "disabled";
	};

	sio@E804F800 {
		compatible = "hisilicon,hi3630-sio";
		reg = <0x0 0xE804F800 0x0 0x400>;
		status = "disabled";
	};

	sio@E804FC00 {
		compatible = "hisilicon,hi3630-sio";
		reg = <0x0 0xE804FC00 0x0 0x400>;
		status = "disabled";
	};

	asp_dmac@E804B000 {
		compatible = "hisilicon,hi3630-pcm-asp-dma";
		reg = <0x0 0xe804b000 0x0 0x1000>;
		asp-dmac-supply = <&asp>;
		interrupts = <0 216 4>;
		interrupt-names = "asp_dma_irq";
		status = "disabled";
	};

	asp_dmac@E804B000 {
		compatible = "hisilicon,soundtrigger_dma_drv";
		reg = <0x0 0xe804b000 0x0 0x1000>;
		asp-dmac-supply = <&asp>;
		interrupts = <0 216 4>;
		interrupt-names = "asp_dma_irq";
		status = "ok";
	};

	hifidsp {
		compatible = "hisilicon,k3hifidsp";
		status = "ok";
	};

	sochifi_watchdog {
		compatible = "hisilicon,sochifi-watchdog";
		interrupts = <0 213 4>;
		status = "ok";
	};

	audio_hw_config {
		product_name = "FRD";
		spk_pa_name = "max98925";
		cust_name = "audio_custom";
		soc_name = "hi363x";
		codec_name = "hi6402";
		codec_dsp_algo = "maxim|mad";
		modem_sio_master = "true";
		ear_pa_name = "none";
		vqm_enable = "true";
		multi_mic_enable = "false";
		status = "ok";
		audio_capability {
			bwe_ui_support = "false";
			bwe_support = "true";
			wnr_support = "false";
			lvm_support = "true";
			dhf_support = "false";
			dual_smartpa_support = "false";
			spk_rcv_stereo_support = "false";
		};
	};

	deviceboxID: deviceboxID@0 {
		check_mode = "gpio";
		box_num = <1>;
		enable_boxID = <1 0 0 0>;
		gpio_num = <1 0 0 0>;
		gpio_speakerID = <&gpio29 1 0>;
		speaker_map = <1 2>;/*1 means AAC, 2 means GEER*/

		pinctrl-names = "default", "idle";
		pinctrl-0 = <&gpio009_hi6402_pinctrl_func>;
		pinctrl-1 = <&gpio009_hi6402_pinctrl_idle>;
		deviceboxID_limit = <500>;
		status = "ok";
	};

	hw_soundtrigger_event: hw_soundtrigger_event{
		status = "ok";
	};

	/* audio device end */

	/* eMMC0 */
	sdhci0: sdhci@FF390000 {
		vmmc-supply=<&ldo15>;
		caps2-mmc-hs400-1_8v;/*caps2-mmc-hs400-1_8v, caps2-mmc-hs200-1_8v, caps2-mmc-ddr50-1_8v*/
		/*caps2-mmc-packed-command;*/
		keep-power-in-suspend;
		/*caps2-mmc-poweroff-notify;*/
		/*caps2-mmc-enhanced_strobe-ctrl;*/
		/*caps2-mmc-cache_flush_barrier-ctrl;*/
		caps2-mmc-bkops_auto-ctrl;
		caps2-mmc-cmd-queue;
	};

	/* SD */
	dwmmc1: dwmmc1@FF37F000 {
		vmmc-supply = <&ldo16>;
		vqmmc-supply = <&ldo9>;
		cd-vol = <1>;
		cd-gpio = <&gpio25 3 0>;
		shared-irq = <1>;
		status = "ok";
	};

	/* wifi */
	dwmmc2: dwmmc2@ff3ff000 {
		sdio_support_uhs;
		caps2-support-wifi;
		status = "ok";
	};

	bcm_wifi {
		wlan-irq,gpio-irq = <&gpio23 2 0>;
		wlan-on,gpio-enable= <&gpio0 1 0>;
		wlan_enable,gpio_vio = <&gpio16 3 0>;
		pinctrl-0 = <&gpio061_cfg_func &gpio062_cfg_func
				&gpio063_cfg_func &gpio064_cfg_func
				&gpio065_cfg_func &gpio066_cfg_func
				&gpio131_cfg_func
				&gpio061_pmx_func &gpio062_pmx_func
				&gpio063_pmx_func &gpio064_pmx_func
				&gpio065_pmx_func &gpio066_pmx_func
				&gpio131_pmx_func>;
		pinctrl-1 = <&gpio061_cfg_idle &gpio062_cfg_idle
				&gpio063_cfg_idle &gpio064_cfg_idle
				&gpio065_cfg_idle &gpio066_cfg_idle
				&gpio131_cfg_idle
				&gpio061_pmx_idle &gpio062_pmx_idle
				&gpio063_pmx_idle &gpio064_pmx_idle
				&gpio065_pmx_idle &gpio066_pmx_idle
				&gpio131_pmx_idle>;
		wifi_nvram_name = "/vendor/firmware/nvram43455_hw_frd_tucl.txt";
		wifi_fw_name = "/vendor/firmware/fw_bcm43455_hw.bin";
		wifi_fw_ap_name = "/vendor/firmware/fw_bcm43455_apsta_hw.bin";
		wifi_fw_test_name = "/vendor/firmware/fw_bcm43455_test_hw_apsta.bin";
		ic_type = "bcm43455";
	};

	pmic@FFF34000 {
		ldo19: ldo@7C {
			regulator-always-on;
		};
	};

	touchscreen {
		product = "frd";
		bus_id = <0>;
		has_virtualkey = <0>;
		fpga_flag = <0>;
		support_chip_name = "synaptics","atmel";
		synaptics: touchscreen@70 {
			algo_id = <1>;
			ic_type = <2>;
			vci_gpio_type = <0>;
			vci_regulator_type = <1>;
			vddio_gpio_type = <0>;
			vddio_regulator_type = <1>;
			reset_gpio = <&gpio24 1 0>;
			attn_gpio = <&gpio24 0 0>;
			pinctrl-names = "default", "idle";
			pinctrl-0 = <&gpio192_cfg_func &gpio193_cfg_func>;
			pinctrl-1 = <&gpio192_cfg_idle &gpio193_cfg_idle>;
			synaptics-vdd-supply = <&ldo17>;
			synaptics-io-supply = <&ldo4>;
			slave_address = <0x70>;
			irq_config = <0>;
			x_max = <1080>;
			y_max = <1920>;
			x_max_mt = <1080>;
			y_max_mt = <1920>;
			raw_data_limit = "4000", /*rawdata-max*/
					 "1000", /*rawdata-min*/
					 "50", /*deltadata-max*/
					 "-50", /*deltadata-min*/
					 "700", /*rx-to-rx-diff-max*/
					 "-700", /*rx-to-rx-diff-min*/
					 "700", /*tx-to-tx-diff-max*/
					 "-700";/*tx-to-tx-diff-min*/
			vci_value = <3300000>;
			FRD_18100 {
				compatible = "synaptics-FRD_18100";
				ic_type = <3>;
				report_rate_test = <0>;
				supported_func_indicater = <0x21>;
				raw_data_limit = "579", "112", "40", "-40", "120", "-120", "120", "-120";
				holster_switch_addr = <0x001C>;
				holster_switch_bit = <1>;
				glove_switch_addr = <0x001C>;
				glove_switch_bit = <0>;
				roi_supported = <1>;
				roi_control_addr = <0x043A>;
				roi_control_bit = <0>;
				roi_data_addr = <0x0418>;
				should_check_tp_calibration_info = <1>;
			};
			FRD_11080{
				compatible = "synaptics-FRD_11080";
				x_max = <1080>;
				y_max = <1920>;
				x_max_mt = <1080>;
				y_max_mt = <1920>;
				holster_switch_addr = <0x0419>;
				holster_switch_bit = <0>;
				glove_switch_addr = <0x001E>;
				glove_switch_bit = <0>;
				roi_supported = <1>;
				roi_control_addr = <0x041B>;
				roi_control_bit = <0>;
				roi_data_addr = <0x0418>;
				raw_data_limit = "3047", "983", "40", "-40", "1300", "-1300", "1300", "-1300";
				test_enhance_raw_data_capacitance = <1>;
				huawei,enhance_rawdata_upperlimit =
				<2583 2707 2824 2753 2840 2754 2847 2717 2930 2752 2957 2737 2899 2798 2953 2720 2866 2788 2874 2805 2867 2741 2918 2753 2905 2745 2805 2592
				2234 2226 2242 2204 2219 2187 2242 2211 2254 2241 2265 2230 2256 2232 2268 2211 2250 2210 2263 2221 2267 2220 2267 2225 2273 2216 2273 2187
				2168 2200 2187 2174 2180 2165 2210 2193 2220 2220 2232 2210 2226 2212 2236 2191 2224 2189 2239 2203 2242 2200 2242 2207 2250 2198 2252 2168
				2174 2208 2194 2185 2204 2191 2234 2216 2243 2246 2263 2234 2252 2236 2260 2215 2251 2211 2263 2228 2268 2224 2265 2230 2272 2220 2273 2191
				2146 2180 2169 2164 2182 2172 2213 2195 2230 2226 2237 2228 2242 2219 2241 2195 2226 2195 2242 2208 2250 2204 2246 2210 2254 2200 2268 2173
				2146 2180 2168 2167 2177 2172 2210 2195 2221 2226 2239 2247 2242 2265 2239 2198 2228 2211 2245 2208 2250 2207 2247 2211 2255 2200 2258 2173
				2178 2208 2199 2189 2203 2194 2230 2220 2243 2247 2258 2255 2255 2272 2263 2226 2255 2230 2267 2232 2275 2232 2271 2234 2277 2226 2308 2195
				2148 2184 2176 2169 2180 2173 2204 2198 2215 2226 2224 2224 2212 2212 2226 2195 2215 2195 2236 2212 2247 2215 2246 2216 2251 2219 2268 2200
				2148 2187 2174 2176 2180 2178 2200 2200 2208 2232 2215 2224 2200 2223 2208 2211 2189 2219 2207 2241 2215 2242 2216 2246 2225 2246 2230 2239
				2169 2215 2195 2199 2200 2200 2220 2225 2229 2259 2234 2246 2219 2252 2224 2246 2208 2255 2224 2271 2234 2268 2234 2267 2236 2263 2230 2255
				2147 2187 2174 2172 2180 2178 2199 2203 2204 2236 2210 2224 2195 2230 2200 2220 2184 2230 2200 2243 2208 2242 2211 2247 2215 2242 2206 2228
				2148 2187 2169 2169 2174 2180 2194 2203 2199 2232 2206 2230 2193 2228 2198 2216 2180 2223 2197 2236 2204 2239 2207 2246 2212 2237 2203 2224
				2172 2212 2189 2191 2191 2199 2213 2228 2224 2255 2226 2246 2215 2243 2215 2232 2194 2236 2211 2251 2219 2255 2221 2258 2228 2252 2216 2239
				2152 2195 2172 2198 2168 2176 2203 2220 2219 2260 2224 2247 2215 2220 2189 2208 2169 2215 2187 2230 2194 2228 2195 2232 2203 2229 2191 2213
				2172 2256 2200 2241 2187 2221 2216 2267 2236 2307 2275 2304 2262 2289 2241 2250 2203 2250 2221 2252 2212 2247 2212 2251 2223 2247 2211 2229
				2359 2975 2758 2964 2762 2964 2789 2925 2866 2958 2874 2965 2787 3047 2854 2944 2775 3013 2793 3010 2809 2930 2883 2913 2895 2886 2821 2467>;
				huawei,enhance_rawdata_lowerlimit =
				<1120 1221 1288 1244 1280 1235 1287 1218 1330 1225 1330 1221 1304 1237 1319 1207 1278 1230 1267 1232 1263 1202 1277 1207 1277 1205 1222 1128
				1029 1027 1048 1029 1039 1033 1050 1034 1057 1039 1049 1036 1048 1036 1050 1028 1041 1029 1041 1025 1042 1022 1040 1026 1048 1024 1041 1000
				998 1014 1023 1018 1018 1020 1030 1021 1038 1028 1032 1026 1032 1024 1033 1016 1027 1019 1028 1013 1029 1011 1028 1015 1036 1014 1032 990
				1004 1023 1032 1028 1027 1031 1039 1030 1046 1037 1041 1035 1041 1033 1042 1025 1035 1028 1036 1022 1039 1021 1037 1025 1046 1024 1042 1001
				994 1015 1021 1018 1017 1020 1029 1022 1037 1028 1032 1026 1032 1024 1032 1016 1027 1019 1027 1015 1030 1012 1028 1015 1036 1015 1032 990
				996 1016 1019 1018 1015 1017 1028 1022 1036 1028 1031 1026 1011 1013 1032 1016 1026 1018 1028 1013 1029 1012 1026 1015 1037 1015 1032 990
				1006 1024 1029 1026 1024 1027 1036 1030 1045 1036 1039 1033 1029 1023 1041 1025 1035 1028 1036 1022 1038 1021 1035 1023 1046 1024 1042 998
				995 1015 1018 1018 1013 1018 1025 1022 1032 1027 1026 1026 1026 1023 1026 1015 1022 1015 1024 1013 1027 1013 1025 1017 1034 1020 1032 998
				992 1015 1015 1018 1009 1020 1022 1023 1028 1029 1021 1029 1020 1026 1018 1022 1011 1026 1011 1024 1014 1025 1009 1027 1021 1032 1013 1014
				1003 1028 1024 1031 1021 1032 1032 1036 1039 1043 1032 1045 1032 1044 1027 1038 1022 1040 1021 1036 1023 1037 1019 1039 1027 1040 1015 1022
				994 1017 1018 1020 1011 1022 1023 1026 1029 1034 1022 1035 1022 1034 1019 1029 1011 1032 1011 1028 1013 1027 1009 1029 1018 1032 1005 1013
				995 1018 1019 1021 1013 1024 1024 1029 1032 1036 1024 1037 1023 1036 1020 1030 1013 1033 1013 1029 1015 1028 1010 1032 1018 1032 1007 1015
				1007 1031 1029 1034 1024 1034 1034 1043 1043 1048 1036 1048 1034 1046 1031 1041 1023 1043 1024 1040 1025 1040 1021 1041 1029 1043 1019 1025
				998 1023 1021 1025 1015 1027 1026 1034 1034 1039 1027 1041 983 1020 1021 1032 1015 1034 1015 1031 1015 1030 1013 1034 1020 1034 1010 1015
				1007 1055 1032 1050 1027 1050 1038 1054 1047 1057 1040 1059 1004 1010 1034 1048 1027 1049 1026 1045 1026 1043 1025 1046 1032 1046 1022 1026
				1071 1316 1225 1327 1227 1330 1234 1300 1270 1316 1263 1314 1225 1342 1242 1291 1205 1316 1206 1303 1202 1259 1240 1254 1236 1242 1204 1081>;
			};
			FRD_11081{
				compatible = "synaptics-FRD_11081";
				x_max = <1080>;
				y_max = <1920>;
				x_max_mt = <1080>;
				y_max_mt = <1920>;
				holster_switch_addr = <0x0419>;
				holster_switch_bit = <0>;
				glove_switch_addr = <0x001E>;
				glove_switch_bit = <0>;
				roi_supported = <1>;
				roi_control_addr = <0x041B>;
				roi_control_bit = <0>;
				roi_data_addr = <0x0418>;
				raw_data_limit = "3047", "983", "40", "-40", "1300", "-1300", "1300", "-1300";
				test_enhance_raw_data_capacitance = <1>;
				report_rate_test = <1>;
				huawei,trx_short_array_num = <4>;
				huawei,trx_short_circuit_array = <0x00 0x00 0x00 0x00>;
				huawei,enhance_rawdata_upperlimit =
				<2583 2707 2824 2753 2840 2754 2847 2717 2930 2752 2957 2737 2899 2798 2953 2720 2866 2788 2874 2805 2867 2741 2918 2753 2905 2745 2805 2592
				2234 2226 2242 2204 2219 2187 2242 2211 2254 2241 2265 2230 2256 2232 2268 2211 2250 2210 2263 2221 2267 2220 2267 2225 2273 2216 2273 2187
				2168 2200 2187 2174 2180 2165 2210 2193 2220 2220 2232 2210 2226 2212 2236 2191 2224 2189 2239 2203 2242 2200 2242 2207 2250 2198 2252 2168
				2174 2208 2194 2185 2204 2191 2234 2216 2243 2246 2263 2234 2252 2236 2260 2215 2251 2211 2263 2228 2268 2224 2265 2230 2272 2220 2273 2191
				2146 2180 2169 2164 2182 2172 2213 2195 2230 2226 2237 2228 2242 2219 2241 2195 2226 2195 2242 2208 2250 2204 2246 2210 2254 2200 2268 2173
				2146 2180 2168 2167 2177 2172 2210 2195 2221 2226 2239 2247 2242 2265 2239 2198 2228 2211 2245 2208 2250 2207 2247 2211 2255 2200 2258 2173
				2178 2208 2199 2189 2203 2194 2230 2220 2243 2247 2258 2255 2255 2272 2263 2226 2255 2230 2267 2232 2275 2232 2271 2234 2277 2226 2308 2195
				2148 2184 2176 2169 2180 2173 2204 2198 2215 2226 2224 2224 2212 2212 2226 2195 2215 2195 2236 2212 2247 2215 2246 2216 2251 2219 2268 2200
				2148 2187 2174 2176 2180 2178 2200 2200 2208 2232 2215 2224 2200 2223 2208 2211 2189 2219 2207 2241 2215 2242 2216 2246 2225 2246 2230 2239
				2169 2215 2195 2199 2200 2200 2220 2225 2229 2259 2234 2246 2219 2252 2224 2246 2208 2255 2224 2271 2234 2268 2234 2267 2236 2263 2230 2255
				2147 2187 2174 2172 2180 2178 2199 2203 2204 2236 2210 2224 2195 2230 2200 2220 2184 2230 2200 2243 2208 2242 2211 2247 2215 2242 2206 2228
				2148 2187 2169 2169 2174 2180 2194 2203 2199 2232 2206 2230 2193 2228 2198 2216 2180 2223 2197 2236 2204 2239 2207 2246 2212 2237 2203 2224
				2172 2212 2189 2191 2191 2199 2213 2228 2224 2255 2226 2246 2215 2243 2215 2232 2194 2236 2211 2251 2219 2255 2221 2258 2228 2252 2216 2239
				2152 2195 2172 2198 2168 2176 2203 2220 2219 2260 2224 2247 2215 2220 2189 2208 2169 2215 2187 2230 2194 2228 2195 2232 2203 2229 2191 2213
				2172 2256 2200 2241 2187 2221 2216 2267 2236 2307 2275 2304 2262 2289 2241 2250 2203 2250 2221 2252 2212 2247 2212 2251 2223 2247 2211 2229
				2359 2975 2758 2964 2762 2964 2789 2925 2866 2958 2874 2965 2787 3047 2854 2944 2775 3013 2793 3010 2809 2930 2883 2913 2895 2886 2821 2467>;
				huawei,enhance_rawdata_lowerlimit =
				<1373 1474 1585 1509 1588 1509 1592 1470 1644 1469 1652 1453 1609 1491 1625 1448 1577 1478 1557 1484 1541 1449 1567 1450 1546 1446 1485 1345
				1234 1230 1255 1233 1259 1234 1258 1234 1267 1234 1266 1226 1258 1237 1261 1227 1258 1226 1251 1230 1252 1229 1262 1231 1262 1227 1262 1198
				1187 1205 1214 1206 1221 1207 1224 1208 1230 1210 1232 1203 1229 1212 1230 1205 1232 1203 1227 1207 1229 1210 1240 1213 1242 1210 1244 1182
				1198 1218 1226 1218 1233 1220 1235 1222 1242 1222 1243 1214 1239 1224 1242 1217 1242 1214 1238 1220 1242 1220 1252 1225 1254 1222 1258 1193
				1186 1206 1214 1208 1222 1210 1224 1210 1230 1211 1232 1203 1227 1213 1230 1206 1230 1203 1227 1210 1230 1210 1242 1214 1243 1211 1246 1183
				1186 1206 1214 1207 1221 1208 1223 1210 1230 1210 1231 1202 1226 1212 1230 1205 1230 1204 1226 1208 1230 1210 1240 1214 1244 1210 1246 1182
				1191 1215 1222 1217 1230 1218 1233 1220 1241 1219 1242 1211 1238 1222 1240 1214 1241 1214 1237 1219 1239 1219 1249 1224 1252 1221 1256 1192
				1173 1204 1201 1205 1208 1206 1210 1207 1219 1207 1219 1198 1218 1210 1222 1203 1224 1202 1223 1208 1227 1210 1239 1217 1243 1217 1248 1192
				1170 1208 1198 1210 1205 1210 1205 1214 1210 1215 1210 1210 1206 1223 1208 1218 1208 1219 1205 1226 1210 1229 1221 1236 1225 1237 1225 1214
				1184 1227 1210 1226 1216 1230 1216 1234 1222 1237 1220 1231 1217 1243 1218 1236 1218 1234 1214 1241 1218 1241 1226 1246 1227 1243 1223 1222
				1170 1213 1198 1214 1204 1218 1204 1222 1210 1223 1210 1218 1205 1230 1207 1222 1206 1222 1202 1227 1205 1230 1214 1232 1215 1231 1210 1212
				1169 1212 1197 1213 1202 1217 1203 1221 1208 1222 1208 1217 1204 1230 1206 1222 1205 1220 1201 1226 1204 1226 1213 1230 1213 1230 1210 1210
				1179 1225 1208 1225 1214 1229 1214 1232 1219 1234 1219 1227 1214 1240 1217 1232 1216 1230 1213 1236 1214 1238 1224 1242 1223 1239 1219 1220
				1169 1216 1197 1216 1202 1219 1202 1221 1207 1223 1207 1217 1202 1227 1206 1220 1204 1218 1198 1224 1202 1226 1212 1229 1210 1226 1206 1207
				1194 1268 1224 1262 1230 1261 1230 1260 1234 1258 1234 1251 1226 1260 1230 1248 1225 1246 1220 1249 1222 1246 1233 1249 1230 1243 1221 1220
				1242 1604 1465 1623 1469 1620 1467 1592 1501 1599 1498 1599 1455 1642 1484 1578 1444 1593 1438 1582 1440 1531 1484 1515 1484 1488 1442 1250>;
			huawei,tx_delta_abslimit =
				<750 750 750 750 750 750 750 750 750 750 750 750 750 750 750 750 750 750 750 750 750 750 750 750 750 750 750 750
				150 150 150 150 150 150 150 150 150 150 150 150 150 150 150 150 150 150 150 150 150 150 150 150 150 150 150 150
				150 150 150 150 150 150 150 150 150 150 150 150 150 150 150 150 150 150 150 150 150 150 150 150 150 150 150 150
				150 150 150 150 150 150 150 150 150 150 150 150 150 150 150 150 150 150 150 150 150 150 150 150 150 150 150 150
				150 150 150 150 150 150 150 150 150 150 150 150 150 150 150 150 150 150 150 150 150 150 150 150 150 150 150 150
				150 150 150 150 150 150 150 150 150 150 150 150 150 150 150 150 150 150 150 150 150 150 150 150 150 150 150 150
				150 150 150 150 150 150 150 150 150 150 150 150 150 150 150 150 150 150 150 150 150 150 150 150 150 150 150 150
				150 150 150 150 150 150 150 150 150 150 150 150 150 150 150 150 150 150 150 150 150 150 150 150 150 150 150 150
				150 150 150 150 150 150 150 150 150 150 150 150 150 150 150 150 150 150 150 150 150 150 150 150 150 150 150 150
				150 150 150 150 150 150 150 150 150 150 150 150 150 150 150 150 150 150 150 150 150 150 150 150 150 150 150 150
				150 150 150 150 150 150 150 150 150 150 150 150 150 150 150 150 150 150 150 150 150 150 150 150 150 150 150 150
				150 150 150 150 150 150 150 150 150 150 150 150 150 150 150 150 150 150 150 150 150 150 150 150 150 150 150 150
				150 150 150 150 150 150 150 150 150 150 150 150 150 150 150 150 150 150 150 150 150 150 150 150 150 150 150 150
				150 150 150 150 150 150 150 150 150 150 150 150 150 150 150 150 150 150 150 150 150 150 150 150 150 150 150 150
				750 750 750 750 750 750 750 750 750 750 750 750 750 750 750 750 750 750 750 750 750 750 750 750 750 750 750 750>;
			huawei,rx_delta_abslimit =
				<750 750 750 750 750 750 750 750 750 750 750 750 750 750 750 750 750 750 750 750 750 750 750 750 750 750 750
				200 150 150 150 150 150 150 150 150 150 150 150 150 150 150 150 150 150 150 150 150 150 150 150 150 150 200
				200 150 150 150 150 150 150 150 150 150 150 150 150 150 150 150 150 150 150 150 150 150 150 150 150 150 200
				200 150 150 150 150 150 150 150 150 150 150 150 150 150 150 150 150 150 150 150 150 150 150 150 150 150 200
				200 150 150 150 150 150 150 150 150 150 150 150 150 150 150 150 150 150 150 150 150 150 150 150 150 150 200
				200 150 150 150 150 150 150 150 150 150 150 150 150 150 150 150 150 150 150 150 150 150 150 150 150 150 200
				200 150 150 150 150 150 150 150 150 150 150 150 150 150 150 150 150 150 150 150 150 150 150 150 150 150 200
				200 150 150 150 150 150 150 150 150 150 150 150 150 150 150 150 150 150 150 150 150 150 150 150 150 150 200
				200 150 150 150 150 150 150 150 150 150 150 150 150 150 150 150 150 150 150 150 150 150 150 150 150 150 200
				200 150 150 150 150 150 150 150 150 150 150 150 150 150 150 150 150 150 150 150 150 150 150 150 150 150 200
				200 150 150 150 150 150 150 150 150 150 150 150 150 150 150 150 150 150 150 150 150 150 150 150 150 150 200
				200 150 150 150 150 150 150 150 150 150 150 150 150 150 150 150 150 150 150 150 150 150 150 150 150 150 200
				200 150 150 150 150 150 150 150 150 150 150 150 150 150 150 150 150 150 150 150 150 150 150 150 150 150 200
				200 150 150 150 150 150 150 150 150 150 150 150 150 150 150 150 150 150 150 150 150 150 150 150 150 150 200
				200 150 150 150 150 150 150 150 150 150 150 150 150 150 150 150 150 150 150 150 150 150 150 150 150 150 200
				750 750 750 750 750 750 750 750 750 750 750 750 750 750 750 750 750 750 750 750 750 750 750 750 750 750 750>;
			};
		};
		atmel: touchscreen@4b{
			compatible = "atmel";
			y_max_mt = <1920>;
			x_max_mt = <1080>;
			y_max = <1920>;
			x_max = <1080>;
			slave_address = <0x4a>;
			irq_config = <0>;
			atmel-vddio-supply = <&ldo4>;
			atmel-avdd-supply = <&ldo17>;
			pinctrl-1 = <&gpio192_cfg_idle &gpio193_cfg_idle>;
			pinctrl-0 = <&gpio192_cfg_func &gpio193_cfg_func>;
			pinctrl-names = "default", "idle";
			attn_gpio = <&gpio24 0 0>;
			reset_gpio = <&gpio24 1 0>;
			vddio_regulator_type = <1>;
			vddio_gpio_type = <0>;
			vci_regulator_type = <1>;
			vci_gpio_type = <0>;
			algo_id = <2>;
			raw_data_limit = "29500", "24500", "100", "-100", "3000", "-3000", "3000", "-3000";
			FRD_19160 {
				compatible = "FRD_19160";
				x_max = <1080>;
				y_max = <1920>;
				x_max_mt = <1080>;
				y_max_mt = <1920>;
				producer = "SHARP";
				description = "frd_sharp_fhd";
				roi_supported = <1>;
				charger_supported = <1>;
			};
		};
	};

	sensorhub_status{
		compatible = "huawei,sensorhub_status";
		status="ok";
	};

	sensorhub_nmi{
		compatible = "huawei,sensorhub_nmi";
		nmi_reg=<0x598>;
	};

	gps_power:gps_power{
		status = "ok";
		huawei,gps_en = <&gpio15 2 0>;
		huawei,gps_hostwake = <&gpio26 2 0>;
		huawei,mcu_req = <&gpio17 2 0>;
		huawei,mcu_req_rsp = <&gpio15 1 0>;
		pinctrl-0 = <&gpio016_pmx_func &gpio016_cfg_func>;
		pinctrl-1 = <&gpio016_pmx_idle &gpio016_cfg_idle>;
		huawei,gps_refclk = <16>;
		broadcom_config,ic_type= "bcm4774";
		broadcom_config,tty_port="ttyAMA3";
	};

	sensorhub{
		#address-cells=<1>;
		#size-cells=<0>;
		als_sensor:light{
			als1{
				compatible="huawei,rohm_bh1745";
				reg=<0x38>;
				chip_id_value=<0xE0>;
				file_id=<38>;
				poll_interval=<350>;
				gpio_int1=<&gpio26 6 0>;
				als_phone_type = <14>;
				als_phone_version = <10>;
				als_extend_data = <0 0 0 0 0 0 0 0 0 0 0 0>;
				status = "ok";
				sensorlist_name="light-bh1745";
				vendor="rohm";
				sensor_list_info_id = <3>;
			};
			als2{
				compatible="huawei,avago_apds9251";
				bus_number = <0x0>;
				reg=<0x52>;
				chip_id_register = <0x06>;
				chip_id_value = <0xB2>;
				file_id = <41>;
				sensor_list_info_id = <3>;
				sensor_type = "als";
				poll_interval = <120>;
				threshold_value = <0x1>;
				GA1 = <0x1046>;
				GA2 = <0xf3c>;
				GA3 = <0x1194>;
				tp_color = <0x0>;
				again = <0x1>;
				gpio_int1 = <0x38 0x6 0x0>;
				atime = <0xdb>;
				init_time = <0x96>;
				status = "ok";
				als_phone_type = <14>;
				als_phone_version = <10>;
				als_extend_data = <0x0 0x0 0x0 0x0 0x0 0x0 0x0 0x0 0x0 0x0 0x0 0x0>;
				sensorlist_name="als-apds9251";
				vendor="avago";
			};
		};

		ps_sensor:proximity{
			ps1{
				compatible="huawei,txc-pa224";
				reg=<0x1e>;
				chip_id_register=<0x7F>;
				chip_id_value=<0x11>;
				file_id=<39>;
				min_proximity_value=<220>;
				pwindows_value=<8>;
				pwave_value=<12>;
				threshold_value=<25>;
				gpio_int1=<&gpio27 1 0>;
				poll_interval = <100>;
				status = "ok";
				sensorlist_name="proximity";
				vendor="txc";
				sensor_list_info_id = <4>;
			};

		};
		acc_sensor:gsensor{
			acc1{
				compatible="huawei,bosch-bmi160";
				reg=<0x68>;
				chip_id_register=<0x0>;
				chip_id_value=<0xd1>;
				file_id=<33>;
				axis_map_x=<1>;
				axis_map_y=<0>;
				axis_map_z=<2>;
				negate_x=<1>;
				negate_y=<1>;
				negate_z=<1>;
				offset_x=<0>;
				offset_y=<0>;
				offset_z=<0>;
				gpio_int2=<&gpio26 5 0>;
				status = "ok";
				sensorlist_name="accelerometer-bmi160";
				vendor="bosch";
				minDelay=<10000>;
				fifoReservedEventCount=<0>;
				fifoMaxEventCount=<0>;
				sensor_list_info_id =<0>;
			};
			acc2{
				compatible="huawei,st-lsm6ds3";
				bus_number=<0>;
				reg=<0x6a>;
				chip_id_register=<0x0f>;
				chip_id_value=<0x69>;
				file_id=<34>;
				sensor_list_info_id=<0>;
				sensor_type="acc";
				/*sensor-vdd-supply = <&ldo24>;*/
				axis_map_x=<0>;
				axis_map_y=<1>;
				axis_map_z=<2>;
				negate_x=<0>;
				negate_y=<1>;
				negate_z=<1>;
				offset_x=<0>;
				offset_y=<0>;
				offset_z=<0>;
				poll_interval=<10>;
				gpio_int1=<&gpio26 0 0>;
				gpio_int2=<&gpio26 5 0>;
				status = "ok";
				sensorlist_name="accelerometer";
				vendor="st";
				minDelay=<10000>;
				fifoReservedEventCount=<0>;
				fifoMaxEventCount=<0>;
			};
		};

		gyro_sensor:gyroscope{
			gyro1{
				compatible ="huawei,bosch-bmi160";
				reg=<0x68>;
				chip_id_register=<0x0>;
				chip_id_value=<0xd1>;
				file_id=<35>;
				axis_map_x=<1>;
				axis_map_y=<0>;
				axis_map_z=<2>;
				negate_x=<1>;
				negate_y=<1>;
				negate_z=<1>;
				gpio_int2=<&gpio26 5 0>;
				status = "ok";
				sensorlist_name="gyroscope-bmi160";
				vendor="bosch";
				minDelay=<10000>;
				fifoReservedEventCount=<0>;
				fifoMaxEventCount=<0>;
				sensor_list_info_id=<5>;
			};
			gyro2{
				compatible ="huawei,st-lsm6ds3";
				bus_number=<0>;
				reg=<0x6a>;
				chip_id_register=<0x0f>;
				chip_id_value=<0x69>;
				file_id=<36>;
				sensor_list_info_id=<5>;
				sensor_type="gyro";
				/*sensor-vdd-supply = <&ldo24>;*/
				axis_map_x=<0>;
				axis_map_y=<1>;
				axis_map_z=<2>;
				negate_x=<0>;
				negate_y=<1>;
				negate_z=<1>;
				poll_interval=<10>;
				gpio_int1=<&gpio26 2 0>;
				gpio_int2=<&gpio26 5 0>;
				status = "ok";
				sensorlist_name="gyroscope-lsm6ds3";
				vendor="st";
				minDelay=<10000>;
				fifoReservedEventCount=<0>;
				fifoMaxEventCount=<0>;
			};
		};
		mag_sensor:compass{
			mag1{
				compatible="huawei,akm-akm09911";
				bus_number=<0>;
				reg=<0x0d>;
				chip_id_register=<0x00>;
				chip_id_value=<0x48>;
				file_id=<37>;
				sensor_list_info_id=<1>;
				sensor_type="mag";
				/*sensor-vdd-supply = <&ldo24>;*/
				outbit=<0>;
				calibrate_method=<2>;
				axis_map_x=<1>;
				axis_map_y=<0>;
				axis_map_z=<2>;
				negate_x=<0>;
				negate_y=<0>;
				negate_z=<1>;
				poll_interval=<10>;
				gpio_int1=<&gpio0 0 0>;
				gpio_reset=<&gpio0 0 0>;
				softiron_parameter = <16 39 0 0 0 0 0 0 16 39 0 0 0 0 0 0 16 39 0 0 0 0 0 0 0 0 0>;
				status = "ok";
				sensorlist_name="mag-akm09911";
				vendor="akm";
				minDelay=<10000>;
				fifoReservedEventCount=<0>;
				fifoMaxEventCount=<0>;
				maxDelay=<0>;
			};
		};
		gps_i2c_sensor:gps_4774_i2c{
			gps_4774_i2c{
				compatible="huawei,gps_4774_i2c";
				bus_number=<0>;
				reg=<0x6e>;
				chip_id_register=<0x91>;
				chip_id_value=<0x00>;
				file_id=<61>;
				sensor_list_info_id=<0x23>;
				sensor_type="gps_4774_i2c";
				status = "ok";
			};
		};
	};

	sensorhub_ext_config:sensorhub_ex{
		compatible = "huawei,sensorhub";
		akm_need_current = "no";
		invensense_exist = "no";
		isensor_version = "no";
		adapt_file_id = <9 18>;
		adapt_sensor_list_id = <2 6 7 8 11 12 13 14 15 17 18 21>;
	};

	sensorhub_io_power{
		compatible = "huawei,sensorhub_io";
		sensor-io-supply = <&ldo24>;
		status="ok";
	};

	hall {
		compatible = "huawei,hall_sensor,ak8789";
		status = "ok";
		huawei,hall_1{
			huawei,single-n-pole = <&gpio23 1 0>;
			huawei,type = <0x01>;
			huawei,id = <0>;
			huawei,default-state = "on";
			huawei,wakeup-flag = <0x4000>;
			huawei,hw-wakeup-support = <0x3>;
			huawei,x-coordinate = <0x0>;
			huawei,y-coordinate = <0x0>;
		};
	};
	/*
		device check : the 0 means that it don't need to check;
			the 1 means that it check at board check and running test;
			the 2 means that it check at running test
	*/
	devcheck: devcheck {
		touch_panel = <2>;
		compass = <1>;
		g_sensor = <1>;
		gyroscope = <1>;
		nfc = <1>;
		dc_dc = <1>;
		tps = <1>;
		l_sensor = <2>;
		charge = <1>;
		usb_switch = <1>;
		wifi = <1>;
		bt = <1>;
		gps = <1>;
		antenna_ctl = <0>;
		airpress = <0>;
		vibrator_lra = <1>;
		laser = <1>;
		camera_pmic = <1>;
		anc_max14744 = <1>;
		cpu_chip = <1>;
		status = "ok";
	};

	viacbp82d_power:viacbp82d_power {
		compatible = "huawei,viacbp82d-power";
		via_pwr_en = <&gpio13 7 0>;	      // modem power enable,    111
		via_rst_mdm = <&gpio11 1 0>;	      // reset modem,           89
		via_reset_ind = <&gpio27 3 0>;	      //rst ind      219
		via_reset_ind_connect_to_codec = <0x0>;		//reset_indication is connected to hi6402 codec?
		via_backup = <&gpio3 6 0>;            // ap notify via produce ramdump 30

		status = "ok";
	};
	viacbp82d_cbp_spi:viacbp82d_cbp_spi {
		compatible = "huawei,viacbp82d-cbp-spi";
		via_data_ack = <&gpio12 6 0>;          // modem data ack,        102
		via_flow_ctrl = <&gpio12 5 0>;         // modem flow control,    101
		via_ap_abort_cp = <&gpio12 2 0>;       // ap abort cp,           98
		via_ap_wkup_cp = <&gpio14 1 0>;        // ap wakeup cp,          113
		via_cp_ready = <&gpio27 0 0>;         // cp ready,              216
		via_cp_wkup_ap = <&gpio26 4 0>;       // cp wakeup ap,          212
		via_ap_ready = <&gpio3 5 0>;         // ap ready,              029

		status = "ok";
	};

	rnic_adapter:rnic_adapter {
		status = "ok";
	};

	viacbp82d_flashless_boot_dl_uart:viacbp82d_flashless_boot_dl_uart {
		uart_port = "1";
		status = "ok";
	};

	//via modem sdio1
	dwmmc3: dwmmc3@FF37D000 {
		status = "ok";
		modem_sdio_enable;
		keep-power-in-suspend;
		keep-power-ignore-pm-notify;
		caps2-support-via-modem;//this host is connected by via cbp8.2 modem
	    vmmc-supply = <&ldo15>;
	};

	bluetooth_power:bluetooth_power{
		huawei,vio_en = <131>;
		huawei,bt_en = <6>;
		status = "ok";
	};

	bluetooth_sleep:bluetooth_sleep{
		huawei,bt_wake_host = <222>;
		huawei,host_wake_bt = <100>;
		status = "ok";
	};

    
	huawei,hisi_isp100{
		status = "ok";
		pinctrl-names = "default", "idle";
		hisi,is_fpga = <0>;
		pinctrl-1 = <
				&gpio017_pmx_idle	//SMCAM_RST
				&gpio018_pmx_idle	//MCAM1_RST
				&gpio134_pmx_idle	//MCAM2_RST
				&gpio022_pmx_idle	//ISP_CCLK0
				&gpio023_pmx_idle	//ISP_CCLK1
				&gpio024_pmx_idle	//ISP_CCLK2
				&gpio025_pmx_idle	//ISP_SCL0
				&gpio026_pmx_idle	//ISP_SDA0
				&gpio027_pmx_idle	//ISP_SCL1
				&gpio028_pmx_idle	//ISP_SDA1
				//&gpio003_hi6402_pinctrl_idle	//SCAM_ID
				//&gpio025_hi6402_pinctrl_idle	//LDO4_IOVDD_1V8 Enable

				&gpio017_cfg_idle	//SMCAM_RST
				&gpio018_cfg_idle	//MCAM1_RST
				&gpio134_cfg_idle	//MCAM2_RST
				&gpio022_cfg_idle	//ISP_CCLK0
				&gpio023_cfg_idle	//ISP_CCLK1
				&gpio024_cfg_idle	//ISP_CCLK2
				&gpio025_cfg_idle	//ISP_SCL0
				&gpio026_cfg_idle	//ISP_SDA0
				&gpio027_cfg_idle	//ISP_SCL1
				&gpio028_cfg_idle	//ISP_SDA1
				>;
		pinctrl-0 = <
				&gpio017_pmx_func	//SMCAM_RST
				&gpio018_pmx_func	//MCAM1_RST
				&gpio134_pmx_func	//MCAM2_RST
				&gpio022_pmx_func	//ISP_CCLK0
				&gpio023_pmx_func	//ISP_CCLK1
				&gpio024_pmx_func	//ISP_CCLK2
				&gpio025_pmx_func	//ISP_SCL0
				&gpio026_pmx_func	//ISP_SDA0
				&gpio027_pmx_func	//ISP_SCL1
				&gpio028_pmx_func	//ISP_SDA1
				//&gpio003_hi6402_pinctrl_func	//SCAM_ID
				//&gpio025_hi6402_pinctrl_func	//LDO4_IOVDD_1V8 Enable

				&gpio017_cfg_func	//SMCAM_RST
				&gpio018_cfg_func	//MCAM1_RST
				&gpio134_cfg_func	//MCAM2_RST
				&gpio022_cfg_func	//ISP_CCLK0
				&gpio023_cfg_func	//ISP_CCLK1
				&gpio024_cfg_func	//ISP_CCLK2
				&gpio025_cfg_func	//ISP_SCL0
				&gpio026_cfg_func	//ISP_SDA0
				&gpio027_cfg_func	//ISP_SCL1
				&gpio028_cfg_func	//ISP_SDA1				
				>;
	};

	
	huawei,imx179d_knt{
		compatible = "huawei,imx179d_knt";
		huawei,sensor_name = "IMX179";
		huawei,sensor_index = <1>;
		huawei,is_fpga = <0>;
		huawei,pd_valid = <1>;
		huawei,reset_valid = <1>;
		huawei,vcmpd_valid = <0>;
		huawei,csi_index = <0x2>;
		huawei,i2c_index = <0x0>;
		status = "ok";
		vcm-supply = <&ldo25>;		//Cam0 vcm just for test
		huawei,ldo-names = "vcm";
		huawei,mclk = <24000000>;
		clock-names = "clk_isp_snclk2";
		clocks = <&clk_gate_isp_snclk2>;
		gpios = <&gpio2 1 0 &gpio28 3 0>;
		huawei,gpio-ctrl-types = "reset", "fsin";
	};

	huawei,ov8865_knt{
		compatible = "huawei,ov8865_knt";
		huawei,sensor_name = "OV8865_2L";
		huawei,sensor_index = <1>;
		huawei,is_fpga = <0>;
		huawei,pd_valid = <1>;
		huawei,reset_valid = <1>;
		huawei,vcmpd_valid = <0>;
		huawei,csi_index = <0x2>;
		huawei,i2c_index = <0x0>;
		status = "ok";
		vcm-supply = <&ldo25>;		//Cam0 vcm just for test
		huawei,ldo-names = "vcm";
		huawei,mclk = <24000000>;
		clock-names = "clk_isp_snclk2";
		clocks = <&clk_gate_isp_snclk2>;
		gpios = <&gpio2 1 0 &gpio28 3 0>;
		huawei,gpio-ctrl-types = "reset", "fsin";
	};

	huawei,imx278{
		huawei,is_fpga = <0>;
		clocks = <&clk_gate_isp_snclk0>;
		clock-names = "clk_isp_snclk0";
		huawei,mclk = <16000000>;
		avdd-supply = <&ldo13>;
		dvdd-supply = <&ldo32>;
		avdd2-supply = <&ldo19>;
		dvdd2-supply = <&ldo20>;
		huawei,ldo-names = "avdd", "dvdd", "avdd2", "dvdd2";
		gpios = <&gpio2 2 0 &gpio2 1 0 &gpio15 2 0>;
		huawei,gpio-ctrl-types = "reset", "suspend", "ldo_en";
		status = "disabled";
	};

	huawei,imx230{
		huawei,is_fpga = <0>;
		clocks = <&clk_gate_isp_snclk0>;
		clock-names = "clk_isp_snclk0";
		huawei,mclk = <24000000>;
		avdd-supply = <&ldo13>;
		dvdd-supply = <&ldo32>;
		avdd2-supply = <&ldo19>;
		dvdd2-supply = <&ldo20>;
		huawei,ldo-names = "avdd", "dvdd", "avdd2", "dvdd2";

		gpios = <&gpio2 2 0 &gpio2 1 0 &gpio1 4 0>;
		huawei,gpio-ctrl-types = "reset", "suspend", "ldo_en";
		status = "disable";
	};

	huawei,imx214{
		status = "disable";
	};

	huawei,imx286d_knt{
		compatible = "huawei,imx286d_knt";
		huawei,sensor_name = "IMX286DUAL";
		huawei,sensor_index = <0>;
		huawei,is_fpga = <0>;
		huawei,pd_valid = <1>;
		huawei,reset_valid = <1>;
		huawei,vcmpd_valid = <0>;
		huawei,csi_index = <1 0>;
		huawei,i2c_index = <1 0>;
		clocks = <&clk_gate_isp_snclk0 &clk_gate_isp_snclk1>;
		clock-names = "clk_isp_snclk0", "clk_isp_snclk1";
		huawei,mclk = <24000000>;

		dvdd-supply = <&ldo20>;	    //Cam0 dvdd
		dvdd2-supply = <&ldo32>;	//Cam1 dvdd
		vcm-supply = <&ldo25>;		//Cam0 vcm
		vcm2-supply = <&ldo13>;		//Cam1 vcm
		huawei,ldo-names = "dvdd", "dvdd2", "vcm", "vcm2";

		gpios = <&gpio2 2 0 &gpio16 6 0 &gpio28 1 0>;
		huawei,gpio-ctrl-types = "reset", "reset2", "mispdcdc-en";
		status = "ok";
	};

	huawei,imx214d_knt{
		compatible = "huawei,imx214d_knt";
		huawei,sensor_name = "IMX214DUAL";
		huawei,sensor_index = <0>;
		huawei,is_fpga = <0>;
		huawei,pd_valid = <1>;
		huawei,reset_valid = <1>;
		huawei,vcmpd_valid = <0>;
		huawei,csi_index = <1 0>;
		huawei,i2c_index = <1 0>;
		clocks = <&clk_gate_isp_snclk0 &clk_gate_isp_snclk1>;
		clock-names = "clk_isp_snclk0", "clk_isp_snclk1";
		huawei,mclk = <24000000>;

		
		dvdd-supply = <&ldo20>;	    //Cam0 dvdd
		dvdd2-supply = <&ldo32>;	//Cam1 dvdd
		vcm-supply = <&ldo25>;		//Cam0 vcm
		vcm2-supply = <&ldo13>;		//Cam1 vcm
		huawei,ldo-names = "dvdd", "dvdd2", "vcm", "vcm2";

		gpios = <&gpio2 2 0 &gpio16 6 0 &gpio28 1 0>;
		huawei,gpio-ctrl-types = "reset", "reset2", "mispdcdc-en";
		status = "disable";
	};

	huawei,imx179{
		huawei,is_fpga = <0>;
		clocks = <&clk_gate_isp_snclk2>;
		clock-names = "clk_isp_snclk2";
		huawei,mclk = <24000000>;

		gpios = <&gpio2 1 0>;
		huawei,gpio-ctrl-types = "reset";
		status = "disable";
	};

	huawei,imx298{
		huawei,is_fpga = <0>;
		clocks = <&clk_gate_isp_snclk0>;
		clock-names = "clk_isp_snclk0";
		huawei,mclk = <24000000>;
		avdd-supply = <&ldo13>;
		dvdd-supply = <&ldo32>;
		avdd2-supply = <&ldo19>;
		dvdd2-supply = <&ldo20>;
		vcm-supply = <&ldo25>;
		huawei,ldo-names = "avdd", "dvdd", "avdd2", "dvdd2", "vcm";

		gpios = <&gpio2 2 0 &gpio2 1 0 &gpio15 2 0 &gpio28 0 0 &gpio3 6 0>;
		huawei,gpio-ctrl-types = "reset", "suspend", "ldo_en", "fsin", "ois";
		status = "disable";
	};

	huawei,ald2 {
		compatible = "huawei,ald2";
		status = "ok";
	};

   

	nfc_exist {
		nfc_exist_flag = "1";
		nfc_ese_spi_det = "1";
		status = "ok";
	};

	ese_config {
		spi_bus = <1>;
		gpio_spi_cs = <14>;
		gpio_ese_irq = <10>;
		gpio_ese_reset = <9>;
		svdd_pwr_req_need = <1>;
		gpio_svdd_pwr_req = <50>;
		spi_switch_need = <0>;
		gpio_spi_switch = <0>;
		status = "ok";
	};


    
	pmic: pmic@FFF34000 {
		sim0 {
			gpios = <&gpio25 3 0>;
			status = "ok";
			func_sel_state = "not_use_multi_func";
			det_normal_direction = "closed";
			allocate_gpio = <0>;
			shared_det_irq = <1>;
			send_msg_to_cp = <1>;
			card_tray_style = <1>;
			hpd_interrupt_to_close_ldo = <0x22>;
			hpd_debounce_wait_time = <0x22>;
			det_debounce_wait_time = <300>;
			interrupt-parent = <&pmic>;
			interrupts = <25 0>;
			interrupt-names = "hpd0_falling";
			send_card_out_msg_when_init = <1>;
		};

		sim1 {
			gpios = <&gpio25 3 0>;
			status = "ok";
			func_sel_state = "not_use_multi_func";
			det_normal_direction = "closed";
			allocate_gpio = <0>;
			shared_det_irq = <1>;
			send_msg_to_cp = <1>;
			card_tray_style = <1>;
			hpd_interrupt_to_close_ldo = <0x22>;
			hpd_debounce_wait_time = <0x22>;
			det_debounce_wait_time = <300>;
			interrupt-parent = <&pmic>;
			interrupts = <29 0>;
			interrupt-names = "hpd1_falling";
			send_card_out_msg_when_init = <1>;
		};
	};
    

	hisi_usb@ff200000{
		eye_diagram_param = <0x3fda6e4>;
		eye_diagram_host_param = <0x2cdc6e7>;
	};

    thermal-zones {
        soc_thermal {
                       governor_name = "power_allocator";
                       polling-delay = <1000>;
                       polling-delay-passive = <250>;
                       sustainable-power = <2500>;

                       thermal-sensors = <&ipa_sensor0 255>;

                       trips {
                                 threshold: trip-point@0 {
                                            temperature = <55000>;
                                            hysteresis = <1000>;
                                            type = "passive";
                                };
                                target: trip-point@1 {
                                           temperature = <80000>;
                                           hysteresis = <1000>;
                                           type = "passive";
                                };
                        };

                        cooling-maps {
                                   map0 {
                                           trip = <&target>;
                                           cooling-device = <&cluster0 0xffffffff 0xffffffff>;
                                           contribution = <768>;
                                   };
                                   map1 {
                                           trip = <&target>;
                                           cooling-device = <&cluster1 0xffffffff 0xffffffff>;
                                           contribution = <256>;
                                   };
                                   map2 {
                                           trip = <&target>;
                                           cooling-device = <&gpu 0xffffffff 0xffffffff>;
                                           contribution = <256>;
                                   };
                        };

                    };
    };

	fingerprint {
		compatible = "fpc,fingerprint";
		fingerprint,product = "faraday";
		spi-max-frequency = <5000000>;

		fingerprint,force_storage_type = "SFS";
		fingerprint,fpc2050 = <1>;
		fingerprint,reset_gpio = <112>;
		fingerprint,cs_gpio = <15>;
		fingerprint,irq_gpio = <198>;

		pinctrl-names = "default", "idle";
		pinctrl-0 = <&gpio112_pmx_func &gpio112_cfg_func &gpio198_pmx_func &gpio198_cfg_func>;
		pinctrl-1 = <&gpio112_pmx_idle &gpio112_cfg_idle &gpio198_pmx_idle &gpio198_cfg_idle>;
	};
};
